VERSION ""
//Author: Matthew Nice

NS_ :

BS_:

BU_: XXX

BO_ 116 PEDAL_CMD: 12 XXX
 SG_ TORQUE_CMD_CCM : 86|12@0+ (1,0) [0|4000] "" XXX
 SG_ ACCEL_THROTTLE : 43|10@0+ (1,0) [0|4000] "" XXX
 SG_ ACCEL_PEDAL_DRIVER : 49|10@0+ (1,0) [0|4000] "" XXX

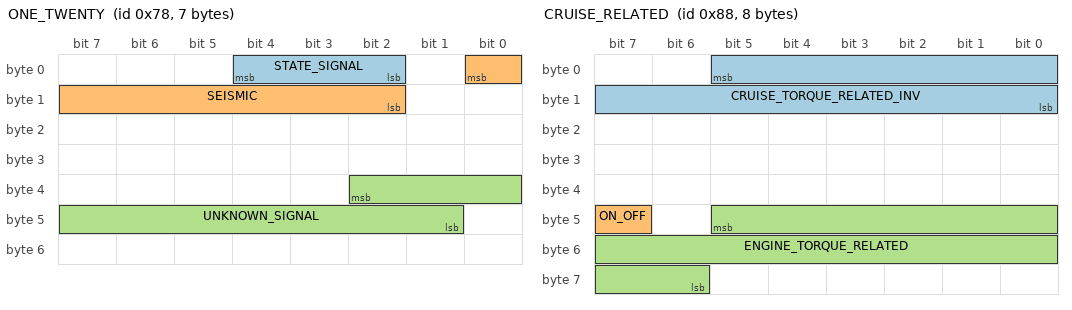
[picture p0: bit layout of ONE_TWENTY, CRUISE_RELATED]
BO_ 120 ONE_TWENTY: 7 XXX
 SG_ STATE_SIGNAL : 4|3@0+ (1,0) [0|4000] "" XXX
 SG_ SEISMIC : 0|7@0+ (1,0) [0|4000] "" XXX
 SG_ UNKNOWN_SIGNAL : 34|10@0+ (1,0) [0|4000] "" XXX

BO_ 136 CRUISE_RELATED: 8 XXX
 SG_ CRUISE_TORQUE_RELATED_INV : 5|14@0+ (1,0) [0|4000] "" XXX
 SG_ ON_OFF : 47|1@0+ (1,0) [0|1] "" XXX
 SG_ ENGINE_TORQUE_RELATED : 45|16@0+ (1,0) [0|50000] "" XXX

BO_ 139 STEER_ANGLE: 48 XXX
 SG_ STEER_ANGLE : 55|16@0+ (0.05,0) [0|500] "" XXX
 SG_ STEER_ANGLE_REPEAT : 208|16@0+ (0.05,0) [0|500] "" XXX

BO_ 140 PEDAL_THROTTLE: 48 XXX
 SG_ ACCEL_PEDAL_POSITION: 43|10@0+ (1,0) [0|1000] "" XXX
 SG_ ACCEL_PEDAL_POSITION_REPEAT: 49|10@0+ (1,0) [0|200] "" XXX
 SG_ RPM_RELATED: 86|12@0+ (0.05,0) [0|4000] "" XXX
 SG_ WHEEL_TORQUE_CMD_RELATED: 139|16@0+ (0.05,0) [0|100000] "" XXX
 SG_ RPM: 167|16@0+ (0.14285,0) [0|100000] "" XXX
 SG_ WHEEL_TORQUE_CMD_RELATED_2: 183|10@0+ (0.05,0) [0|100000] "" XXX

BO_ 141 STEERING_WHEEL: 24 XXX
 SG_ STEER_ANGLE: 55|18@0+ (1,0) [0|140000] "" XXX
 SG_ STEER_RATE: 66|12@0+ (1,0) [0|4000] "" XXX
 SG_ STEER_RELATED_YAW: 86|11@0+ (1,0) [0|1000] "" XXX

BO_ 168 STEERING_2: 24 XXX
 SG_ STEER_ANGLE: 55|12@0+ (1,0) [0|140000] "" XXX
 SG_ STEER_RATE: 79|16@0+ (1,0) [0|4000] "" XXX

BO_ 286 TWO_EIGHTY_SIX: 3 XXX
 SG_ WHEEL_TORQUE_CMD: 5|15@0+ (1,0) [0|100] "" XXX

BO_ 303 SPEED: 12 XXX
 SG_ GEAR: 55|6@0+ (1,0) [0|64] "" XXX
 SG_ WHEEL_TORQUE: 60|12@0+ (1,0) [0|4000] "" XXX
 SG_ SPEED : 77|12@0+ (0.048,0) [0|65535] "kph" XXX

BO_ 308 CRUISE: 64 XXX
 SG_ CRUISE_TORQUE_STATE : 57|4@0+ (1,0) [0|16] "" XXX
 SG_ WHEEL_TORQUE_CMD : 68|12@0+ (1,0) [0|4000] "" XXX
 SG_ STEER_ANGLE_BUT_NOT : 151|16@0+ (1,0) [0|40000] "" XXX
 SG_ BRAKE_TORQUE_ACTIVE : 160|1@0+ (1,0) [0|1] "" XXX
 SG_ BRAKE_TORQUE_CMD : 170|10@0+ (1,0) [0|1000] "" XXX
 SG_ CRUISE_STATE : 306|4@0+ (1,0) [0|32] "" XXX
 SG_ CRUISE_ENGAGED : 321|1@0+ (1,0) [0|1] "" XXX

BO_ 381 LEFT_RADAR_1: 64 Vector__XXX
	SG_ NEARBY_WARNING_FLAG_6 : 484|1@0+ (1,0) [0|0] "unit" Vector__XXX
	SG_ INVALID_6 : 473|1@0+ (1,0) [0|0] "unit" Vector__XXX
	SG_ VALID_B_6 : 475|1@0+ (1,0) [0|0] "unit" Vector__XXX
	SG_ VALID_A_6 : 478|1@0+ (1,0) [0|0] "unit" Vector__XXX
	SG_ MYSTERY_RELATIVE_VELOCITY_6 : 460|13@0- (1,0) [0|0] "unit" Vector__XXX
	SG_ ABSOLUTE_DISTANCE_6 : 442|13@0+ (0.0176,0.1163) [0|0] "m" Vector__XXX
	SG_ ANGLE_6 : 431|9@0+ (0.0033,0.4509) [0|0] "radians" Vector__XXX
	SG_ BEHIND_FLAG_6 : 416|1@0+ (1,0) [0|0] "unit" Vector_XXX
	SG_ SIGNAL_QUESTION_A_6 : 422|6@0- (1,0) [0|0] "unit" Vector__XXX

	SG_ NEARBY_WARNING_FLAG_5 : 412|1@0+ (1,0) [0|0] "unit" Vector__XXX
	SG_ INVALID_5 : 401|1@0+ (1,0) [0|0] "unit" Vector__XXX
	SG_ VALID_B_5 : 403|1@0+ (1,0) [0|0] "unit" Vector__XXX
	SG_ VALID_A_5 : 406|1@0+ (1,0) [0|0] "unit" Vector__XXX
	SG_ MYSTERY_RELATIVE_VELOCITY_5 : 388|13@0- (1,0) [0|0] "unit" Vector__XXX
	SG_ ABSOLUTE_DISTANCE_5 : 370|13@0+ (0.0176,0.1163) [0|0] "m" Vector__XXX
	SG_ ANGLE_5 : 359|9@0+ (0.0033,0.4509) [0|0] "radians" Vector__XXX
	SG_ BEHIND_FLAG_5 : 344|1@0+ (1,0) [0|0] "unit" Vector_XXX
	SG_ SIGNAL_QUESTION_A_5 : 350|6@0- (1,0) [0|0] "unit" Vector__XXX

	SG_ NEARBY_WARNING_FLAG_4 : 340|1@0+ (1,0) [0|0] "unit" Vector__XXX
	SG_ INVALID_4 : 329|1@0+ (1,0) [0|0] "unit" Vector__XXX
	SG_ VALID_B_4 : 331|1@0+ (1,0) [0|0] "unit" Vector__XXX
	SG_ VALID_A_4 : 334|1@0+ (1,0) [0|0] "unit" Vector__XXX
	SG_ MYSTERY_RELATIVE_VELOCITY_4 : 316|13@0- (1,0) [0|0] "unit" Vector__XXX
	SG_ ABSOLUTE_DISTANCE_4 : 298|13@0+ (0.0176,0.1163) [0|0] "m" Vector__XXX
	SG_ ANGLE_4 : 287|9@0+ (0.0033,0.4509) [0|0] "radians" Vector__XXX
	SG_ BEHIND_FLAG_4 : 272|1@0+ (1,0) [0|0] "unit" Vector_XXX
	SG_ SIGNAL_QUESTION_A_4 : 278|6@0- (1,0) [0|0] "unit" Vector__XXX

	SG_ NEARBY_WARNING_FLAG_3 : 268|1@0+ (1,0) [0|0] "unit" Vector__XXX
	SG_ INVALID_3 : 257|1@0+ (1,0) [0|0] "unit" Vector__XXX
	SG_ VALID_B_3 : 259|1@0+ (1,0) [0|0] "unit" Vector__XXX
	SG_ VALID_A_3 : 262|1@0+ (1,0) [0|0] "unit" Vector__XXX
	SG_ MYSTERY_RELATIVE_VELOCITY_3 : 244|13@0- (1,0) [0|0] "unit" Vector__XXX
	SG_ ABSOLUTE_DISTANCE_3 : 226|13@0+ (0.0176,0.1163) [0|0] "m" Vector__XXX
	SG_ ANGLE_3 : 215|9@0+ (0.0033,0.4509) [0|0] "radians" Vector__XXX
	SG_ BEHIND_FLAG_3 : 200|1@0+ (1,0) [0|0] "unit" Vector_XXX
	SG_ SIGNAL_QUESTION_A_3 : 206|6@0- (1,0) [0|0] "unit" Vector__XXX

	SG_ NEARBY_WARNING_FLAG_2 : 196|1@0+ (1,0) [0|0] "unit" Vector__XXX
	SG_ INVALID_2 : 185|1@0+ (1,0) [0|0] "unit" Vector__XXX
	SG_ VALID_B_2 : 187|1@0+ (1,0) [0|0] "unit" Vector__XXX
	SG_ VALID_A_2 : 190|1@0+ (1,0) [0|0] "unit" Vector__XXX
	SG_ MYSTERY_RELATIVE_VELOCITY_2 : 172|13@0- (1,0) [0|0] "unit" Vector__XXX
	SG_ ABSOLUTE_DISTANCE_2 : 154|13@0+ (0.0176,0.1163) [0|0] "m" Vector__XXX
	SG_ ANGLE_2 : 143|9@0+ (0.0033,0.4509) [0|0] "radians" Vector__XXX
	SG_ BEHIND_FLAG_2 : 128|1@0+ (1,0) [0|0] "unit" Vector_XXX
	SG_ SIGNAL_QUESTION_A_2 : 134|6@0- (1,0) [0|0] "unit" Vector__XXX

	SG_ NEARBY_WARNING_FLAG_1 : 124|1@0+ (1,0) [0|0] "unit" Vector__XXX
	SG_ INVALID_1 : 113|1@0+ (1,0) [0|0] "unit" Vector__XXX
	SG_ VALID_B_1 : 115|1@0+ (1,0) [0|0] "unit" Vector__XXX
	SG_ VALID_A_1 : 118|1@0+ (1,0) [0|0] "unit" Vector__XXX
	SG_ MYSTERY_RELATIVE_VELOCITY_1 : 100|13@0- (1,0) [0|0] "unit" Vector__XXX
	SG_ ABSOLUTE_DISTANCE_1 : 82|13@0+ (0.0176,0.1163) [0|0] "m" Vector__XXX
	SG_ ANGLE_1 : 71|9@0+ (0.0033,0.4509) [0|0] "radians" Vector__XXX
	SG_ BEHIND_FLAG_1 : 56|1@0+ (1,0) [0|0] "unit" Vector_XXX
	SG_ SIGNAL_QUESTION_A_1 : 62|6@0- (1,0) [0|0] "unit" Vector__XXX

	SG_ COUNTER : 23|8@0+ (1,0) [0|0] "unit" Vector__XXX
	SG_ CHECKSUM : 7|16@0+ (1,0) [0|0] "unit" Vector__XXX

BO_ 382 RIGHT_RADAR_1: 64 Vector__XXX
	SG_ NEARBY_WARNING_FLAG_6 : 484|1@0+ (1,0) [0|0] "unit" Vector__XXX
	SG_ INVALID_6 : 473|1@0+ (1,0) [0|0] "unit" Vector__XXX
	SG_ VALID_B_6 : 475|1@0+ (1,0) [0|0] "unit" Vector__XXX
	SG_ VALID_A_6 : 478|1@0+ (1,0) [0|0] "unit" Vector__XXX
	SG_ MYSTERY_RELATIVE_VELOCITY_6 : 460|13@0- (1,0) [0|0] "unit" Vector__XXX
	SG_ ABSOLUTE_DISTANCE_6 : 442|13@0+ (0.0176,0.1163) [0|0] "m" Vector__XXX
	SG_ ANGLE_6 : 431|9@0+ (0.0033,0.4509) [0|0] "radians" Vector__XXX
	SG_ BEHIND_FLAG_6 : 416|1@0+ (1,0) [0|0] "unit" Vector_XXX
	SG_ SIGNAL_QUESTION_A_6 : 422|6@0- (1,0) [0|0] "unit" Vector__XXX

	SG_ NEARBY_WARNING_FLAG_5 : 412|1@0+ (1,0) [0|0] "unit" Vector__XXX
	SG_ INVALID_5 : 401|1@0+ (1,0) [0|0] "unit" Vector__XXX
	SG_ VALID_B_5 : 403|1@0+ (1,0) [0|0] "unit" Vector__XXX
	SG_ VALID_A_5 : 406|1@0+ (1,0) [0|0] "unit" Vector__XXX
	SG_ MYSTERY_RELATIVE_VELOCITY_5 : 388|13@0- (1,0) [0|0] "unit" Vector__XXX
	SG_ ABSOLUTE_DISTANCE_5 : 370|13@0+ (0.0176,0.1163) [0|0] "m" Vector__XXX
	SG_ ANGLE_5 : 359|9@0+ (0.0033,0.4509) [0|0] "radians" Vector__XXX
	SG_ BEHIND_FLAG_5 : 344|1@0+ (1,0) [0|0] "unit" Vector_XXX
	SG_ SIGNAL_QUESTION_A_5 : 350|6@0- (1,0) [0|0] "unit" Vector__XXX

	SG_ NEARBY_WARNING_FLAG_4 : 340|1@0+ (1,0) [0|0] "unit" Vector__XXX
	SG_ INVALID_4 : 329|1@0+ (1,0) [0|0] "unit" Vector__XXX
	SG_ VALID_B_4 : 331|1@0+ (1,0) [0|0] "unit" Vector__XXX
	SG_ VALID_A_4 : 334|1@0+ (1,0) [0|0] "unit" Vector__XXX
	SG_ MYSTERY_RELATIVE_VELOCITY_4 : 316|13@0- (1,0) [0|0] "unit" Vector__XXX
	SG_ ABSOLUTE_DISTANCE_4 : 298|13@0+ (0.0176,0.1163) [0|0] "m" Vector__XXX
	SG_ ANGLE_4 : 287|9@0+ (0.0033,0.4509) [0|0] "radians" Vector__XXX
	SG_ BEHIND_FLAG_4 : 272|1@0+ (1,0) [0|0] "unit" Vector_XXX
	SG_ SIGNAL_QUESTION_A_4 : 278|6@0- (1,0) [0|0] "unit" Vector__XXX

	SG_ NEARBY_WARNING_FLAG_3 : 268|1@0+ (1,0) [0|0] "unit" Vector__XXX
	SG_ INVALID_3 : 257|1@0+ (1,0) [0|0] "unit" Vector__XXX
	SG_ VALID_B_3 : 259|1@0+ (1,0) [0|0] "unit" Vector__XXX
	SG_ VALID_A_3 : 262|1@0+ (1,0) [0|0] "unit" Vector__XXX
	SG_ MYSTERY_RELATIVE_VELOCITY_3 : 244|13@0- (1,0) [0|0] "unit" Vector__XXX
	SG_ ABSOLUTE_DISTANCE_3 : 226|13@0+ (0.0176,0.1163) [0|0] "m" Vector__XXX
	SG_ ANGLE_3 : 215|9@0+ (0.0033,0.4509) [0|0] "radians" Vector__XXX
	SG_ BEHIND_FLAG_3 : 200|1@0+ (1,0) [0|0] "unit" Vector_XXX
	SG_ SIGNAL_QUESTION_A_3 : 206|6@0- (1,0) [0|0] "unit" Vector__XXX

	SG_ NEARBY_WARNING_FLAG_2 : 196|1@0+ (1,0) [0|0] "unit" Vector__XXX
	SG_ INVALID_2 : 185|1@0+ (1,0) [0|0] "unit" Vector__XXX
	SG_ VALID_B_2 : 187|1@0+ (1,0) [0|0] "unit" Vector__XXX
	SG_ VALID_A_2 : 190|1@0+ (1,0) [0|0] "unit" Vector__XXX
	SG_ MYSTERY_RELATIVE_VELOCITY_2 : 172|13@0- (1,0) [0|0] "unit" Vector__XXX
	SG_ ABSOLUTE_DISTANCE_2 : 154|13@0+ (0.0176,0.1163) [0|0] "m" Vector__XXX
	SG_ ANGLE_2 : 143|9@0+ (0.0033,0.4509) [0|0] "radians" Vector__XXX
	SG_ BEHIND_FLAG_2 : 128|1@0+ (1,0) [0|0] "unit" Vector_XXX
	SG_ SIGNAL_QUESTION_A_2 : 134|6@0- (1,0) [0|0] "unit" Vector__XXX

	SG_ NEARBY_WARNING_FLAG_1 : 124|1@0+ (1,0) [0|0] "unit" Vector__XXX
	SG_ INVALID_1 : 113|1@0+ (1,0) [0|0] "unit" Vector__XXX
	SG_ VALID_B_1 : 115|1@0+ (1,0) [0|0] "unit" Vector__XXX
	SG_ VALID_A_1 : 118|1@0+ (1,0) [0|0] "unit" Vector__XXX
	SG_ MYSTERY_RELATIVE_VELOCITY_1 : 100|13@0- (1,0) [0|0] "unit" Vector__XXX
	SG_ ABSOLUTE_DISTANCE_1 : 82|13@0+ (0.0176,0.1163) [0|0] "m" Vector__XXX
	SG_ ANGLE_1 : 71|9@0+ (0.0033,0.4509) [0|0] "radians" Vector__XXX
	SG_ BEHIND_FLAG_1 : 56|1@0+ (1,0) [0|0] "unit" Vector_XXX
	SG_ SIGNAL_QUESTION_A_1 : 62|6@0- (1,0) [0|0] "unit" Vector__XXX

	SG_ COUNTER : 23|8@0+ (1,0) [0|0] "unit" Vector__XXX
	SG_ CHECKSUM : 7|16@0+ (1,0) [0|0] "unit" Vector__XXX

BO_ 385 LEFT_RADAR_2: 64 Vector__XXX
	SG_ NEARBY_WARNING_FLAG_6 : 484|1@0+ (1,0) [0|0] "unit" Vector__XXX
	SG_ INVALID_6 : 473|1@0+ (1,0) [0|0] "unit" Vector__XXX
	SG_ VALID_B_6 : 475|1@0+ (1,0) [0|0] "unit" Vector__XXX
	SG_ VALID_A_6 : 478|1@0+ (1,0) [0|0] "unit" Vector__XXX
	SG_ MYSTERY_RELATIVE_VELOCITY_6 : 460|13@0- (1,0) [0|0] "unit" Vector__XXX
	SG_ ABSOLUTE_DISTANCE_6 : 442|13@0+ (0.0176,0.1163) [0|0] "m" Vector__XXX
	SG_ ANGLE_6 : 431|9@0+ (0.0033,0.4509) [0|0] "radians" Vector__XXX
	SG_ BEHIND_FLAG_6 : 416|1@0+ (1,0) [0|0] "unit" Vector_XXX
	SG_ SIGNAL_QUESTION_A_6 : 422|6@0- (1,0) [0|0] "unit" Vector__XXX

	SG_ NEARBY_WARNING_FLAG_5 : 412|1@0+ (1,0) [0|0] "unit" Vector__XXX
	SG_ INVALID_5 : 401|1@0+ (1,0) [0|0] "unit" Vector__XXX
	SG_ VALID_B_5 : 403|1@0+ (1,0) [0|0] "unit" Vector__XXX
	SG_ VALID_A_5 : 406|1@0+ (1,0) [0|0] "unit" Vector__XXX
	SG_ MYSTERY_RELATIVE_VELOCITY_5 : 388|13@0- (1,0) [0|0] "unit" Vector__XXX
	SG_ ABSOLUTE_DISTANCE_5 : 370|13@0+ (0.0176,0.1163) [0|0] "m" Vector__XXX
	SG_ ANGLE_5 : 359|9@0+ (0.0033,0.4509) [0|0] "radians" Vector__XXX
	SG_ BEHIND_FLAG_5 : 344|1@0+ (1,0) [0|0] "unit" Vector_XXX
	SG_ SIGNAL_QUESTION_A_5 : 350|6@0- (1,0) [0|0] "unit" Vector__XXX

	SG_ NEARBY_WARNING_FLAG_4 : 340|1@0+ (1,0) [0|0] "unit" Vector__XXX
	SG_ INVALID_4 : 329|1@0+ (1,0) [0|0] "unit" Vector__XXX
	SG_ VALID_B_4 : 331|1@0+ (1,0) [0|0] "unit" Vector__XXX
	SG_ VALID_A_4 : 334|1@0+ (1,0) [0|0] "unit" Vector__XXX
	SG_ MYSTERY_RELATIVE_VELOCITY_4 : 316|13@0- (1,0) [0|0] "unit" Vector__XXX
	SG_ ABSOLUTE_DISTANCE_4 : 298|13@0+ (0.0176,0.1163) [0|0] "m" Vector__XXX
	SG_ ANGLE_4 : 287|9@0+ (0.0033,0.4509) [0|0] "radians" Vector__XXX
	SG_ BEHIND_FLAG_4 : 272|1@0+ (1,0) [0|0] "unit" Vector_XXX
	SG_ SIGNAL_QUESTION_A_4 : 278|6@0- (1,0) [0|0] "unit" Vector__XXX

	SG_ NEARBY_WARNING_FLAG_3 : 268|1@0+ (1,0) [0|0] "unit" Vector__XXX
	SG_ INVALID_3 : 257|1@0+ (1,0) [0|0] "unit" Vector__XXX
	SG_ VALID_B_3 : 259|1@0+ (1,0) [0|0] "unit" Vector__XXX
	SG_ VALID_A_3 : 262|1@0+ (1,0) [0|0] "unit" Vector__XXX
	SG_ MYSTERY_RELATIVE_VELOCITY_3 : 244|13@0- (1,0) [0|0] "unit" Vector__XXX
	SG_ ABSOLUTE_DISTANCE_3 : 226|13@0+ (0.0176,0.1163) [0|0] "m" Vector__XXX
	SG_ ANGLE_3 : 215|9@0+ (0.0033,0.4509) [0|0] "radians" Vector__XXX
	SG_ BEHIND_FLAG_3 : 200|1@0+ (1,0) [0|0] "unit" Vector_XXX
	SG_ SIGNAL_QUESTION_A_3 : 206|6@0- (1,0) [0|0] "unit" Vector__XXX

	SG_ NEARBY_WARNING_FLAG_2 : 196|1@0+ (1,0) [0|0] "unit" Vector__XXX
	SG_ INVALID_2 : 185|1@0+ (1,0) [0|0] "unit" Vector__XXX
	SG_ VALID_B_2 : 187|1@0+ (1,0) [0|0] "unit" Vector__XXX
	SG_ VALID_A_2 : 190|1@0+ (1,0) [0|0] "unit" Vector__XXX
	SG_ MYSTERY_RELATIVE_VELOCITY_2 : 172|13@0- (1,0) [0|0] "unit" Vector__XXX
	SG_ ABSOLUTE_DISTANCE_2 : 154|13@0+ (0.0176,0.1163) [0|0] "m" Vector__XXX
	SG_ ANGLE_2 : 143|9@0+ (0.0033,0.4509) [0|0] "radians" Vector__XXX
	SG_ BEHIND_FLAG_2 : 128|1@0+ (1,0) [0|0] "unit" Vector_XXX
	SG_ SIGNAL_QUESTION_A_2 : 134|6@0- (1,0) [0|0] "unit" Vector__XXX

	SG_ NEARBY_WARNING_FLAG_1 : 124|1@0+ (1,0) [0|0] "unit" Vector__XXX
	SG_ INVALID_1 : 113|1@0+ (1,0) [0|0] "unit" Vector__XXX
	SG_ VALID_B_1 : 115|1@0+ (1,0) [0|0] "unit" Vector__XXX
	SG_ VALID_A_1 : 118|1@0+ (1,0) [0|0] "unit" Vector__XXX
	SG_ MYSTERY_RELATIVE_VELOCITY_1 : 100|13@0- (1,0) [0|0] "unit" Vector__XXX
	SG_ ABSOLUTE_DISTANCE_1 : 82|13@0+ (0.0176,0.1163) [0|0] "m" Vector__XXX
	SG_ ANGLE_1 : 71|9@0+ (0.0033,0.4509) [0|0] "radians" Vector__XXX
	SG_ BEHIND_FLAG_1 : 56|1@0+ (1,0) [0|0] "unit" Vector_XXX
	SG_ SIGNAL_QUESTION_A_1 : 62|6@0- (1,0) [0|0] "unit" Vector__XXX

	SG_ COUNTER : 23|8@0+ (1,0) [0|0] "unit" Vector__XXX
	SG_ CHECKSUM : 7|16@0+ (1,0) [0|0] "unit" Vector__XXX

BO_ 386 RIGHT_RADAR_2: 64 Vector__XXX
	SG_ NEARBY_WARNING_FLAG_6 : 484|1@0+ (1,0) [0|0] "unit" Vector__XXX
	SG_ INVALID_6 : 473|1@0+ (1,0) [0|0] "unit" Vector__XXX
	SG_ VALID_B_6 : 475|1@0+ (1,0) [0|0] "unit" Vector__XXX
	SG_ VALID_A_6 : 478|1@0+ (1,0) [0|0] "unit" Vector__XXX
	SG_ MYSTERY_RELATIVE_VELOCITY_6 : 460|13@0- (1,0) [0|0] "unit" Vector__XXX
	SG_ ABSOLUTE_DISTANCE_6 : 442|13@0+ (0.0176,0.1163) [0|0] "m" Vector__XXX
	SG_ ANGLE_6 : 431|9@0+ (0.0033,0.4509) [0|0] "radians" Vector__XXX
	SG_ BEHIND_FLAG_6 : 416|1@0+ (1,0) [0|0] "unit" Vector_XXX
	SG_ SIGNAL_QUESTION_A_6 : 422|6@0- (1,0) [0|0] "unit" Vector__XXX

	SG_ NEARBY_WARNING_FLAG_5 : 412|1@0+ (1,0) [0|0] "unit" Vector__XXX
	SG_ INVALID_5 : 401|1@0+ (1,0) [0|0] "unit" Vector__XXX
	SG_ VALID_B_5 : 403|1@0+ (1,0) [0|0] "unit" Vector__XXX
	SG_ VALID_A_5 : 406|1@0+ (1,0) [0|0] "unit" Vector__XXX
	SG_ MYSTERY_RELATIVE_VELOCITY_5 : 388|13@0- (1,0) [0|0] "unit" Vector__XXX
	SG_ ABSOLUTE_DISTANCE_5 : 370|13@0+ (0.0176,0.1163) [0|0] "m" Vector__XXX
	SG_ ANGLE_5 : 359|9@0+ (0.0033,0.4509) [0|0] "radians" Vector__XXX
	SG_ BEHIND_FLAG_5 : 344|1@0+ (1,0) [0|0] "unit" Vector_XXX
	SG_ SIGNAL_QUESTION_A_5 : 350|6@0- (1,0) [0|0] "unit" Vector__XXX

	SG_ NEARBY_WARNING_FLAG_4 : 340|1@0+ (1,0) [0|0] "unit" Vector__XXX
	SG_ INVALID_4 : 329|1@0+ (1,0) [0|0] "unit" Vector__XXX
	SG_ VALID_B_4 : 331|1@0+ (1,0) [0|0] "unit" Vector__XXX
	SG_ VALID_A_4 : 334|1@0+ (1,0) [0|0] "unit" Vector__XXX
	SG_ MYSTERY_RELATIVE_VELOCITY_4 : 316|13@0- (1,0) [0|0] "unit" Vector__XXX
	SG_ ABSOLUTE_DISTANCE_4 : 298|13@0+ (0.0176,0.1163) [0|0] "m" Vector__XXX
	SG_ ANGLE_4 : 287|9@0+ (0.0033,0.4509) [0|0] "radians" Vector__XXX
	SG_ BEHIND_FLAG_4 : 272|1@0+ (1,0) [0|0] "unit" Vector_XXX
	SG_ SIGNAL_QUESTION_A_4 : 278|6@0- (1,0) [0|0] "unit" Vector__XXX

	SG_ NEARBY_WARNING_FLAG_3 : 268|1@0+ (1,0) [0|0] "unit" Vector__XXX
	SG_ INVALID_3 : 257|1@0+ (1,0) [0|0] "unit" Vector__XXX
	SG_ VALID_B_3 : 259|1@0+ (1,0) [0|0] "unit" Vector__XXX
	SG_ VALID_A_3 : 262|1@0+ (1,0) [0|0] "unit" Vector__XXX
	SG_ MYSTERY_RELATIVE_VELOCITY_3 : 244|13@0- (1,0) [0|0] "unit" Vector__XXX
	SG_ ABSOLUTE_DISTANCE_3 : 226|13@0+ (0.0176,0.1163) [0|0] "m" Vector__XXX
	SG_ ANGLE_3 : 215|9@0+ (0.0033,0.4509) [0|0] "radians" Vector__XXX
	SG_ BEHIND_FLAG_3 : 200|1@0+ (1,0) [0|0] "unit" Vector_XXX
	SG_ SIGNAL_QUESTION_A_3 : 206|6@0- (1,0) [0|0] "unit" Vector__XXX

	SG_ NEARBY_WARNING_FLAG_2 : 196|1@0+ (1,0) [0|0] "unit" Vector__XXX
	SG_ INVALID_2 : 185|1@0+ (1,0) [0|0] "unit" Vector__XXX
	SG_ VALID_B_2 : 187|1@0+ (1,0) [0|0] "unit" Vector__XXX
	SG_ VALID_A_2 : 190|1@0+ (1,0) [0|0] "unit" Vector__XXX
	SG_ MYSTERY_RELATIVE_VELOCITY_2 : 172|13@0- (1,0) [0|0] "unit" Vector__XXX
	SG_ ABSOLUTE_DISTANCE_2 : 154|13@0+ (0.0176,0.1163) [0|0] "m" Vector__XXX
	SG_ ANGLE_2 : 143|9@0+ (0.0033,0.4509) [0|0] "radians" Vector__XXX
	SG_ BEHIND_FLAG_2 : 128|1@0+ (1,0) [0|0] "unit" Vector_XXX
	SG_ SIGNAL_QUESTION_A_2 : 134|6@0- (1,0) [0|0] "unit" Vector__XXX

	SG_ NEARBY_WARNING_FLAG_1 : 124|1@0+ (1,0) [0|0] "unit" Vector__XXX
	SG_ INVALID_1 : 113|1@0+ (1,0) [0|0] "unit" Vector__XXX
	SG_ VALID_B_1 : 115|1@0+ (1,0) [0|0] "unit" Vector__XXX
	SG_ VALID_A_1 : 118|1@0+ (1,0) [0|0] "unit" Vector__XXX
	SG_ MYSTERY_RELATIVE_VELOCITY_1 : 100|13@0- (1,0) [0|0] "unit" Vector__XXX
	SG_ ABSOLUTE_DISTANCE_1 : 82|13@0+ (0.0176,0.1163) [0|0] "m" Vector__XXX
	SG_ ANGLE_1 : 71|9@0+ (0.0033,0.4509) [0|0] "radians" Vector__XXX
	SG_ BEHIND_FLAG_1 : 56|1@0+ (1,0) [0|0] "unit" Vector_XXX
	SG_ SIGNAL_QUESTION_A_1 : 62|6@0- (1,0) [0|0] "unit" Vector__XXX

	SG_ COUNTER : 23|8@0+ (1,0) [0|0] "unit" Vector__XXX
	SG_ CHECKSUM : 7|16@0+ (1,0) [0|0] "unit" Vector__XXX

BO_ 389 LEFT_RADAR_3: 64 Vector__XXX
	SG_ NEARBY_WARNING_FLAG_6 : 484|1@0+ (1,0) [0|0] "unit" Vector__XXX
	SG_ INVALID_6 : 473|1@0+ (1,0) [0|0] "unit" Vector__XXX
	SG_ VALID_B_6 : 475|1@0+ (1,0) [0|0] "unit" Vector__XXX
	SG_ VALID_A_6 : 478|1@0+ (1,0) [0|0] "unit" Vector__XXX
	SG_ MYSTERY_RELATIVE_VELOCITY_6 : 460|13@0- (1,0) [0|0] "unit" Vector__XXX
	SG_ ABSOLUTE_DISTANCE_6 : 442|13@0+ (0.0176,0.1163) [0|0] "m" Vector__XXX
	SG_ ANGLE_6 : 431|9@0+ (0.0033,0.4509) [0|0] "radians" Vector__XXX
	SG_ BEHIND_FLAG_6 : 416|1@0+ (1,0) [0|0] "unit" Vector_XXX
	SG_ SIGNAL_QUESTION_A_6 : 422|6@0- (1,0) [0|0] "unit" Vector__XXX

	SG_ NEARBY_WARNING_FLAG_5 : 412|1@0+ (1,0) [0|0] "unit" Vector__XXX
	SG_ INVALID_5 : 401|1@0+ (1,0) [0|0] "unit" Vector__XXX
	SG_ VALID_B_5 : 403|1@0+ (1,0) [0|0] "unit" Vector__XXX
	SG_ VALID_A_5 : 406|1@0+ (1,0) [0|0] "unit" Vector__XXX
	SG_ MYSTERY_RELATIVE_VELOCITY_5 : 388|13@0- (1,0) [0|0] "unit" Vector__XXX
	SG_ ABSOLUTE_DISTANCE_5 : 370|13@0+ (0.0176,0.1163) [0|0] "m" Vector__XXX
	SG_ ANGLE_5 : 359|9@0+ (0.0033,0.4509) [0|0] "radians" Vector__XXX
	SG_ BEHIND_FLAG_5 : 344|1@0+ (1,0) [0|0] "unit" Vector_XXX
	SG_ SIGNAL_QUESTION_A_5 : 350|6@0- (1,0) [0|0] "unit" Vector__XXX

	SG_ NEARBY_WARNING_FLAG_4 : 340|1@0+ (1,0) [0|0] "unit" Vector__XXX
	SG_ INVALID_4 : 329|1@0+ (1,0) [0|0] "unit" Vector__XXX
	SG_ VALID_B_4 : 331|1@0+ (1,0) [0|0] "unit" Vector__XXX
	SG_ VALID_A_4 : 334|1@0+ (1,0) [0|0] "unit" Vector__XXX
	SG_ MYSTERY_RELATIVE_VELOCITY_4 : 316|13@0- (1,0) [0|0] "unit" Vector__XXX
	SG_ ABSOLUTE_DISTANCE_4 : 298|13@0+ (0.0176,0.1163) [0|0] "m" Vector__XXX
	SG_ ANGLE_4 : 287|9@0+ (0.0033,0.4509) [0|0] "radians" Vector__XXX
	SG_ BEHIND_FLAG_4 : 272|1@0+ (1,0) [0|0] "unit" Vector_XXX
	SG_ SIGNAL_QUESTION_A_4 : 278|6@0- (1,0) [0|0] "unit" Vector__XXX

	SG_ NEARBY_WARNING_FLAG_3 : 268|1@0+ (1,0) [0|0] "unit" Vector__XXX
	SG_ INVALID_3 : 257|1@0+ (1,0) [0|0] "unit" Vector__XXX
	SG_ VALID_B_3 : 259|1@0+ (1,0) [0|0] "unit" Vector__XXX
	SG_ VALID_A_3 : 262|1@0+ (1,0) [0|0] "unit" Vector__XXX
	SG_ MYSTERY_RELATIVE_VELOCITY_3 : 244|13@0- (1,0) [0|0] "unit" Vector__XXX
	SG_ ABSOLUTE_DISTANCE_3 : 226|13@0+ (0.0176,0.1163) [0|0] "m" Vector__XXX
	SG_ ANGLE_3 : 215|9@0+ (0.0033,0.4509) [0|0] "radians" Vector__XXX
	SG_ BEHIND_FLAG_3 : 200|1@0+ (1,0) [0|0] "unit" Vector_XXX
	SG_ SIGNAL_QUESTION_A_3 : 206|6@0- (1,0) [0|0] "unit" Vector__XXX

	SG_ NEARBY_WARNING_FLAG_2 : 196|1@0+ (1,0) [0|0] "unit" Vector__XXX
	SG_ INVALID_2 : 185|1@0+ (1,0) [0|0] "unit" Vector__XXX
	SG_ VALID_B_2 : 187|1@0+ (1,0) [0|0] "unit" Vector__XXX
	SG_ VALID_A_2 : 190|1@0+ (1,0) [0|0] "unit" Vector__XXX
	SG_ MYSTERY_RELATIVE_VELOCITY_2 : 172|13@0- (1,0) [0|0] "unit" Vector__XXX
	SG_ ABSOLUTE_DISTANCE_2 : 154|13@0+ (0.0176,0.1163) [0|0] "m" Vector__XXX
	SG_ ANGLE_2 : 143|9@0+ (0.0033,0.4509) [0|0] "radians" Vector__XXX
	SG_ BEHIND_FLAG_2 : 128|1@0+ (1,0) [0|0] "unit" Vector_XXX
	SG_ SIGNAL_QUESTION_A_2 : 134|6@0- (1,0) [0|0] "unit" Vector__XXX

	SG_ NEARBY_WARNING_FLAG_1 : 124|1@0+ (1,0) [0|0] "unit" Vector__XXX
	SG_ INVALID_1 : 113|1@0+ (1,0) [0|0] "unit" Vector__XXX
	SG_ VALID_B_1 : 115|1@0+ (1,0) [0|0] "unit" Vector__XXX
	SG_ VALID_A_1 : 118|1@0+ (1,0) [0|0] "unit" Vector__XXX
	SG_ MYSTERY_RELATIVE_VELOCITY_1 : 100|13@0- (1,0) [0|0] "unit" Vector__XXX
	SG_ ABSOLUTE_DISTANCE_1 : 82|13@0+ (0.0176,0.1163) [0|0] "m" Vector__XXX
	SG_ ANGLE_1 : 71|9@0+ (0.0033,0.4509) [0|0] "radians" Vector__XXX
	SG_ BEHIND_FLAG_1 : 56|1@0+ (1,0) [0|0] "unit" Vector_XXX
	SG_ SIGNAL_QUESTION_A_1 : 62|6@0- (1,0) [0|0] "unit" Vector__XXX

	SG_ COUNTER : 23|8@0+ (1,0) [0|0] "unit" Vector__XXX
	SG_ CHECKSUM : 7|16@0+ (1,0) [0|0] "unit" Vector__XXX

BO_ 390 RIGHT_RADAR_3: 64 Vector__XXX
	SG_ NEARBY_WARNING_FLAG_6 : 484|1@0+ (1,0) [0|0] "unit" Vector__XXX
	SG_ INVALID_6 : 473|1@0+ (1,0) [0|0] "unit" Vector__XXX
	SG_ VALID_B_6 : 475|1@0+ (1,0) [0|0] "unit" Vector__XXX
	SG_ VALID_A_6 : 478|1@0+ (1,0) [0|0] "unit" Vector__XXX
	SG_ MYSTERY_RELATIVE_VELOCITY_6 : 460|13@0- (1,0) [0|0] "unit" Vector__XXX
	SG_ ABSOLUTE_DISTANCE_6 : 442|13@0+ (0.0176,0.1163) [0|0] "m" Vector__XXX
	SG_ ANGLE_6 : 431|9@0+ (0.0033,0.4509) [0|0] "radians" Vector__XXX
	SG_ BEHIND_FLAG_6 : 416|1@0+ (1,0) [0|0] "unit" Vector_XXX
	SG_ SIGNAL_QUESTION_A_6 : 422|6@0- (1,0) [0|0] "unit" Vector__XXX

	SG_ NEARBY_WARNING_FLAG_5 : 412|1@0+ (1,0) [0|0] "unit" Vector__XXX
	SG_ INVALID_5 : 401|1@0+ (1,0) [0|0] "unit" Vector__XXX
	SG_ VALID_B_5 : 403|1@0+ (1,0) [0|0] "unit" Vector__XXX
	SG_ VALID_A_5 : 406|1@0+ (1,0) [0|0] "unit" Vector__XXX
	SG_ MYSTERY_RELATIVE_VELOCITY_5 : 388|13@0- (1,0) [0|0] "unit" Vector__XXX
	SG_ ABSOLUTE_DISTANCE_5 : 370|13@0+ (0.0176,0.1163) [0|0] "m" Vector__XXX
	SG_ ANGLE_5 : 359|9@0+ (0.0033,0.4509) [0|0] "radians" Vector__XXX
	SG_ BEHIND_FLAG_5 : 344|1@0+ (1,0) [0|0] "unit" Vector_XXX
	SG_ SIGNAL_QUESTION_A_5 : 350|6@0- (1,0) [0|0] "unit" Vector__XXX

	SG_ NEARBY_WARNING_FLAG_4 : 340|1@0+ (1,0) [0|0] "unit" Vector__XXX
	SG_ INVALID_4 : 329|1@0+ (1,0) [0|0] "unit" Vector__XXX
	SG_ VALID_B_4 : 331|1@0+ (1,0) [0|0] "unit" Vector__XXX
	SG_ VALID_A_4 : 334|1@0+ (1,0) [0|0] "unit" Vector__XXX
	SG_ MYSTERY_RELATIVE_VELOCITY_4 : 316|13@0- (1,0) [0|0] "unit" Vector__XXX
	SG_ ABSOLUTE_DISTANCE_4 : 298|13@0+ (0.0176,0.1163) [0|0] "m" Vector__XXX
	SG_ ANGLE_4 : 287|9@0+ (0.0033,0.4509) [0|0] "radians" Vector__XXX
	SG_ BEHIND_FLAG_4 : 272|1@0+ (1,0) [0|0] "unit" Vector_XXX
	SG_ SIGNAL_QUESTION_A_4 : 278|6@0- (1,0) [0|0] "unit" Vector__XXX

	SG_ NEARBY_WARNING_FLAG_3 : 268|1@0+ (1,0) [0|0] "unit" Vector__XXX
	SG_ INVALID_3 : 257|1@0+ (1,0) [0|0] "unit" Vector__XXX
	SG_ VALID_B_3 : 259|1@0+ (1,0) [0|0] "unit" Vector__XXX
	SG_ VALID_A_3 : 262|1@0+ (1,0) [0|0] "unit" Vector__XXX
	SG_ MYSTERY_RELATIVE_VELOCITY_3 : 244|13@0- (1,0) [0|0] "unit" Vector__XXX
	SG_ ABSOLUTE_DISTANCE_3 : 226|13@0+ (0.0176,0.1163) [0|0] "m" Vector__XXX
	SG_ ANGLE_3 : 215|9@0+ (0.0033,0.4509) [0|0] "radians" Vector__XXX
	SG_ BEHIND_FLAG_3 : 200|1@0+ (1,0) [0|0] "unit" Vector_XXX
	SG_ SIGNAL_QUESTION_A_3 : 206|6@0- (1,0) [0|0] "unit" Vector__XXX

	SG_ NEARBY_WARNING_FLAG_2 : 196|1@0+ (1,0) [0|0] "unit" Vector__XXX
	SG_ INVALID_2 : 185|1@0+ (1,0) [0|0] "unit" Vector__XXX
	SG_ VALID_B_2 : 187|1@0+ (1,0) [0|0] "unit" Vector__XXX
	SG_ VALID_A_2 : 190|1@0+ (1,0) [0|0] "unit" Vector__XXX
	SG_ MYSTERY_RELATIVE_VELOCITY_2 : 172|13@0- (1,0) [0|0] "unit" Vector__XXX
	SG_ ABSOLUTE_DISTANCE_2 : 154|13@0+ (0.0176,0.1163) [0|0] "m" Vector__XXX
	SG_ ANGLE_2 : 143|9@0+ (0.0033,0.4509) [0|0] "radians" Vector__XXX
	SG_ BEHIND_FLAG_2 : 128|1@0+ (1,0) [0|0] "unit" Vector_XXX
	SG_ SIGNAL_QUESTION_A_2 : 134|6@0- (1,0) [0|0] "unit" Vector__XXX

	SG_ NEARBY_WARNING_FLAG_1 : 124|1@0+ (1,0) [0|0] "unit" Vector__XXX
	SG_ INVALID_1 : 113|1@0+ (1,0) [0|0] "unit" Vector__XXX
	SG_ VALID_B_1 : 115|1@0+ (1,0) [0|0] "unit" Vector__XXX
	SG_ VALID_A_1 : 118|1@0+ (1,0) [0|0] "unit" Vector__XXX
	SG_ MYSTERY_RELATIVE_VELOCITY_1 : 100|13@0- (1,0) [0|0] "unit" Vector__XXX
	SG_ ABSOLUTE_DISTANCE_1 : 82|13@0+ (0.0176,0.1163) [0|0] "m" Vector__XXX
	SG_ ANGLE_1 : 71|9@0+ (0.0033,0.4509) [0|0] "radians" Vector__XXX
	SG_ BEHIND_FLAG_1 : 56|1@0+ (1,0) [0|0] "unit" Vector_XXX
	SG_ SIGNAL_QUESTION_A_1 : 62|6@0- (1,0) [0|0] "unit" Vector__XXX

	SG_ COUNTER : 23|8@0+ (1,0) [0|0] "unit" Vector__XXX
	SG_ CHECKSUM : 7|16@0+ (1,0) [0|0] "unit" Vector__XXX

BO_ 393 LEFT_RADAR_4: 64 Vector__XXX
	SG_ NEARBY_WARNING_FLAG_6 : 484|1@0+ (1,0) [0|0] "unit" Vector__XXX
	SG_ INVALID_6 : 473|1@0+ (1,0) [0|0] "unit" Vector__XXX
	SG_ VALID_B_6 : 475|1@0+ (1,0) [0|0] "unit" Vector__XXX
	SG_ VALID_A_6 : 478|1@0+ (1,0) [0|0] "unit" Vector__XXX
	SG_ MYSTERY_RELATIVE_VELOCITY_6 : 460|13@0- (1,0) [0|0] "unit" Vector__XXX
	SG_ ABSOLUTE_DISTANCE_6 : 442|13@0+ (0.0176,0.1163) [0|0] "m" Vector__XXX
	SG_ ANGLE_6 : 431|9@0+ (0.0033,0.4509) [0|0] "radians" Vector__XXX
	SG_ BEHIND_FLAG_6 : 416|1@0+ (1,0) [0|0] "unit" Vector_XXX
	SG_ SIGNAL_QUESTION_A_6 : 422|6@0- (1,0) [0|0] "unit" Vector__XXX

	SG_ NEARBY_WARNING_FLAG_5 : 412|1@0+ (1,0) [0|0] "unit" Vector__XXX
	SG_ INVALID_5 : 401|1@0+ (1,0) [0|0] "unit" Vector__XXX
	SG_ VALID_B_5 : 403|1@0+ (1,0) [0|0] "unit" Vector__XXX
	SG_ VALID_A_5 : 406|1@0+ (1,0) [0|0] "unit" Vector__XXX
	SG_ MYSTERY_RELATIVE_VELOCITY_5 : 388|13@0- (1,0) [0|0] "unit" Vector__XXX
	SG_ ABSOLUTE_DISTANCE_5 : 370|13@0+ (0.0176,0.1163) [0|0] "m" Vector__XXX
	SG_ ANGLE_5 : 359|9@0+ (0.0033,0.4509) [0|0] "radians" Vector__XXX
	SG_ BEHIND_FLAG_5 : 344|1@0+ (1,0) [0|0] "unit" Vector_XXX
	SG_ SIGNAL_QUESTION_A_5 : 350|6@0- (1,0) [0|0] "unit" Vector__XXX

	SG_ NEARBY_WARNING_FLAG_4 : 340|1@0+ (1,0) [0|0] "unit" Vector__XXX
	SG_ INVALID_4 : 329|1@0+ (1,0) [0|0] "unit" Vector__XXX
	SG_ VALID_B_4 : 331|1@0+ (1,0) [0|0] "unit" Vector__XXX
	SG_ VALID_A_4 : 334|1@0+ (1,0) [0|0] "unit" Vector__XXX
	SG_ MYSTERY_RELATIVE_VELOCITY_4 : 316|13@0- (1,0) [0|0] "unit" Vector__XXX
	SG_ ABSOLUTE_DISTANCE_4 : 298|13@0+ (0.0176,0.1163) [0|0] "m" Vector__XXX
	SG_ ANGLE_4 : 287|9@0+ (0.0033,0.4509) [0|0] "radians" Vector__XXX
	SG_ BEHIND_FLAG_4 : 272|1@0+ (1,0) [0|0] "unit" Vector_XXX
	SG_ SIGNAL_QUESTION_A_4 : 278|6@0- (1,0) [0|0] "unit" Vector__XXX

	SG_ NEARBY_WARNING_FLAG_3 : 268|1@0+ (1,0) [0|0] "unit" Vector__XXX
	SG_ INVALID_3 : 257|1@0+ (1,0) [0|0] "unit" Vector__XXX
	SG_ VALID_B_3 : 259|1@0+ (1,0) [0|0] "unit" Vector__XXX
	SG_ VALID_A_3 : 262|1@0+ (1,0) [0|0] "unit" Vector__XXX
	SG_ MYSTERY_RELATIVE_VELOCITY_3 : 244|13@0- (1,0) [0|0] "unit" Vector__XXX
	SG_ ABSOLUTE_DISTANCE_3 : 226|13@0+ (0.0176,0.1163) [0|0] "m" Vector__XXX
	SG_ ANGLE_3 : 215|9@0+ (0.0033,0.4509) [0|0] "radians" Vector__XXX
	SG_ BEHIND_FLAG_3 : 200|1@0+ (1,0) [0|0] "unit" Vector_XXX
	SG_ SIGNAL_QUESTION_A_3 : 206|6@0- (1,0) [0|0] "unit" Vector__XXX

	SG_ NEARBY_WARNING_FLAG_2 : 196|1@0+ (1,0) [0|0] "unit" Vector__XXX
	SG_ INVALID_2 : 185|1@0+ (1,0) [0|0] "unit" Vector__XXX
	SG_ VALID_B_2 : 187|1@0+ (1,0) [0|0] "unit" Vector__XXX
	SG_ VALID_A_2 : 190|1@0+ (1,0) [0|0] "unit" Vector__XXX
	SG_ MYSTERY_RELATIVE_VELOCITY_2 : 172|13@0- (1,0) [0|0] "unit" Vector__XXX
	SG_ ABSOLUTE_DISTANCE_2 : 154|13@0+ (0.0176,0.1163) [0|0] "m" Vector__XXX
	SG_ ANGLE_2 : 143|9@0+ (0.0033,0.4509) [0|0] "radians" Vector__XXX
	SG_ BEHIND_FLAG_2 : 128|1@0+ (1,0) [0|0] "unit" Vector_XXX
	SG_ SIGNAL_QUESTION_A_2 : 134|6@0- (1,0) [0|0] "unit" Vector__XXX

	SG_ NEARBY_WARNING_FLAG_1 : 124|1@0+ (1,0) [0|0] "unit" Vector__XXX
	SG_ INVALID_1 : 113|1@0+ (1,0) [0|0] "unit" Vector__XXX
	SG_ VALID_B_1 : 115|1@0+ (1,0) [0|0] "unit" Vector__XXX
	SG_ VALID_A_1 : 118|1@0+ (1,0) [0|0] "unit" Vector__XXX
	SG_ MYSTERY_RELATIVE_VELOCITY_1 : 100|13@0- (1,0) [0|0] "unit" Vector__XXX
	SG_ ABSOLUTE_DISTANCE_1 : 82|13@0+ (0.0176,0.1163) [0|0] "m" Vector__XXX
	SG_ ANGLE_1 : 71|9@0+ (0.0033,0.4509) [0|0] "radians" Vector__XXX
	SG_ BEHIND_FLAG_1 : 56|1@0+ (1,0) [0|0] "unit" Vector_XXX
	SG_ SIGNAL_QUESTION_A_1 : 62|6@0- (1,0) [0|0] "unit" Vector__XXX

	SG_ COUNTER : 23|8@0+ (1,0) [0|0] "unit" Vector__XXX
	SG_ CHECKSUM : 7|16@0+ (1,0) [0|0] "unit" Vector__XXX

BO_ 394 RIGHT_RADAR_4: 64 Vector__XXX
	SG_ NEARBY_WARNING_FLAG_6 : 484|1@0+ (1,0) [0|0] "unit" Vector__XXX
	SG_ INVALID_6 : 473|1@0+ (1,0) [0|0] "unit" Vector__XXX
	SG_ VALID_B_6 : 475|1@0+ (1,0) [0|0] "unit" Vector__XXX
	SG_ VALID_A_6 : 478|1@0+ (1,0) [0|0] "unit" Vector__XXX
	SG_ MYSTERY_RELATIVE_VELOCITY_6 : 460|13@0- (1,0) [0|0] "unit" Vector__XXX
	SG_ ABSOLUTE_DISTANCE_6 : 442|13@0+ (0.0176,0.1163) [0|0] "m" Vector__XXX
	SG_ ANGLE_6 : 431|9@0+ (0.0033,0.4509) [0|0] "radians" Vector__XXX
	SG_ BEHIND_FLAG_6 : 416|1@0+ (1,0) [0|0] "unit" Vector_XXX
	SG_ SIGNAL_QUESTION_A_6 : 422|6@0- (1,0) [0|0] "unit" Vector__XXX

	SG_ NEARBY_WARNING_FLAG_5 : 412|1@0+ (1,0) [0|0] "unit" Vector__XXX
	SG_ INVALID_5 : 401|1@0+ (1,0) [0|0] "unit" Vector__XXX
	SG_ VALID_B_5 : 403|1@0+ (1,0) [0|0] "unit" Vector__XXX
	SG_ VALID_A_5 : 406|1@0+ (1,0) [0|0] "unit" Vector__XXX
	SG_ MYSTERY_RELATIVE_VELOCITY_5 : 388|13@0- (1,0) [0|0] "unit" Vector__XXX
	SG_ ABSOLUTE_DISTANCE_5 : 370|13@0+ (0.0176,0.1163) [0|0] "m" Vector__XXX
	SG_ ANGLE_5 : 359|9@0+ (0.0033,0.4509) [0|0] "radians" Vector__XXX
	SG_ BEHIND_FLAG_5 : 344|1@0+ (1,0) [0|0] "unit" Vector_XXX
	SG_ SIGNAL_QUESTION_A_5 : 350|6@0- (1,0) [0|0] "unit" Vector__XXX

	SG_ NEARBY_WARNING_FLAG_4 : 340|1@0+ (1,0) [0|0] "unit" Vector__XXX
	SG_ INVALID_4 : 329|1@0+ (1,0) [0|0] "unit" Vector__XXX
	SG_ VALID_B_4 : 331|1@0+ (1,0) [0|0] "unit" Vector__XXX
	SG_ VALID_A_4 : 334|1@0+ (1,0) [0|0] "unit" Vector__XXX
	SG_ MYSTERY_RELATIVE_VELOCITY_4 : 316|13@0- (1,0) [0|0] "unit" Vector__XXX
	SG_ ABSOLUTE_DISTANCE_4 : 298|13@0+ (0.0176,0.1163) [0|0] "m" Vector__XXX
	SG_ ANGLE_4 : 287|9@0+ (0.0033,0.4509) [0|0] "radians" Vector__XXX
	SG_ BEHIND_FLAG_4 : 272|1@0+ (1,0) [0|0] "unit" Vector_XXX
	SG_ SIGNAL_QUESTION_A_4 : 278|6@0- (1,0) [0|0] "unit" Vector__XXX

	SG_ NEARBY_WARNING_FLAG_3 : 268|1@0+ (1,0) [0|0] "unit" Vector__XXX
	SG_ INVALID_3 : 257|1@0+ (1,0) [0|0] "unit" Vector__XXX
	SG_ VALID_B_3 : 259|1@0+ (1,0) [0|0] "unit" Vector__XXX
	SG_ VALID_A_3 : 262|1@0+ (1,0) [0|0] "unit" Vector__XXX
	SG_ MYSTERY_RELATIVE_VELOCITY_3 : 244|13@0- (1,0) [0|0] "unit" Vector__XXX
	SG_ ABSOLUTE_DISTANCE_3 : 226|13@0+ (0.0176,0.1163) [0|0] "m" Vector__XXX
	SG_ ANGLE_3 : 215|9@0+ (0.0033,0.4509) [0|0] "radians" Vector__XXX
	SG_ BEHIND_FLAG_3 : 200|1@0+ (1,0) [0|0] "unit" Vector_XXX
	SG_ SIGNAL_QUESTION_A_3 : 206|6@0- (1,0) [0|0] "unit" Vector__XXX

	SG_ NEARBY_WARNING_FLAG_2 : 196|1@0+ (1,0) [0|0] "unit" Vector__XXX
	SG_ INVALID_2 : 185|1@0+ (1,0) [0|0] "unit" Vector__XXX
	SG_ VALID_B_2 : 187|1@0+ (1,0) [0|0] "unit" Vector__XXX
	SG_ VALID_A_2 : 190|1@0+ (1,0) [0|0] "unit" Vector__XXX
	SG_ MYSTERY_RELATIVE_VELOCITY_2 : 172|13@0- (1,0) [0|0] "unit" Vector__XXX
	SG_ ABSOLUTE_DISTANCE_2 : 154|13@0+ (0.0176,0.1163) [0|0] "m" Vector__XXX
	SG_ ANGLE_2 : 143|9@0+ (0.0033,0.4509) [0|0] "radians" Vector__XXX
	SG_ BEHIND_FLAG_2 : 128|1@0+ (1,0) [0|0] "unit" Vector_XXX
	SG_ SIGNAL_QUESTION_A_2 : 134|6@0- (1,0) [0|0] "unit" Vector__XXX

	SG_ NEARBY_WARNING_FLAG_1 : 124|1@0+ (1,0) [0|0] "unit" Vector__XXX
	SG_ INVALID_1 : 113|1@0+ (1,0) [0|0] "unit" Vector__XXX
	SG_ VALID_B_1 : 115|1@0+ (1,0) [0|0] "unit" Vector__XXX
	SG_ VALID_A_1 : 118|1@0+ (1,0) [0|0] "unit" Vector__XXX
	SG_ MYSTERY_RELATIVE_VELOCITY_1 : 100|13@0- (1,0) [0|0] "unit" Vector__XXX
	SG_ ABSOLUTE_DISTANCE_1 : 82|13@0+ (0.0176,0.1163) [0|0] "m" Vector__XXX
	SG_ ANGLE_1 : 71|9@0+ (0.0033,0.4509) [0|0] "radians" Vector__XXX
	SG_ BEHIND_FLAG_1 : 56|1@0+ (1,0) [0|0] "unit" Vector_XXX
	SG_ SIGNAL_QUESTION_A_1 : 62|6@0- (1,0) [0|0] "unit" Vector__XXX

	SG_ COUNTER : 23|8@0+ (1,0) [0|0] "unit" Vector__XXX
	SG_ CHECKSUM : 7|16@0+ (1,0) [0|0] "unit" Vector__XXX

BO_ 398 LEFT_RADAR_5: 64 Vector__XXX
	SG_ NEARBY_WARNING_FLAG_6 : 484|1@0+ (1,0) [0|0] "unit" Vector__XXX
	SG_ INVALID_6 : 473|1@0+ (1,0) [0|0] "unit" Vector__XXX
	SG_ VALID_B_6 : 475|1@0+ (1,0) [0|0] "unit" Vector__XXX
	SG_ VALID_A_6 : 478|1@0+ (1,0) [0|0] "unit" Vector__XXX
	SG_ MYSTERY_RELATIVE_VELOCITY_6 : 460|13@0- (1,0) [0|0] "unit" Vector__XXX
	SG_ ABSOLUTE_DISTANCE_6 : 442|13@0+ (0.0176,0.1163) [0|0] "m" Vector__XXX
	SG_ ANGLE_6 : 431|9@0+ (0.0033,0.4509) [0|0] "radians" Vector__XXX
	SG_ BEHIND_FLAG_6 : 416|1@0+ (1,0) [0|0] "unit" Vector_XXX
	SG_ SIGNAL_QUESTION_A_6 : 422|6@0- (1,0) [0|0] "unit" Vector__XXX

	SG_ NEARBY_WARNING_FLAG_5 : 412|1@0+ (1,0) [0|0] "unit" Vector__XXX
	SG_ INVALID_5 : 401|1@0+ (1,0) [0|0] "unit" Vector__XXX
	SG_ VALID_B_5 : 403|1@0+ (1,0) [0|0] "unit" Vector__XXX
	SG_ VALID_A_5 : 406|1@0+ (1,0) [0|0] "unit" Vector__XXX
	SG_ MYSTERY_RELATIVE_VELOCITY_5 : 388|13@0- (1,0) [0|0] "unit" Vector__XXX
	SG_ ABSOLUTE_DISTANCE_5 : 370|13@0+ (0.0176,0.1163) [0|0] "m" Vector__XXX
	SG_ ANGLE_5 : 359|9@0+ (0.0033,0.4509) [0|0] "radians" Vector__XXX
	SG_ BEHIND_FLAG_5 : 344|1@0+ (1,0) [0|0] "unit" Vector_XXX
	SG_ SIGNAL_QUESTION_A_5 : 350|6@0- (1,0) [0|0] "unit" Vector__XXX

	SG_ NEARBY_WARNING_FLAG_4 : 340|1@0+ (1,0) [0|0] "unit" Vector__XXX
	SG_ INVALID_4 : 329|1@0+ (1,0) [0|0] "unit" Vector__XXX
	SG_ VALID_B_4 : 331|1@0+ (1,0) [0|0] "unit" Vector__XXX
	SG_ VALID_A_4 : 334|1@0+ (1,0) [0|0] "unit" Vector__XXX
	SG_ MYSTERY_RELATIVE_VELOCITY_4 : 316|13@0- (1,0) [0|0] "unit" Vector__XXX
	SG_ ABSOLUTE_DISTANCE_4 : 298|13@0+ (0.0176,0.1163) [0|0] "m" Vector__XXX
	SG_ ANGLE_4 : 287|9@0+ (0.0033,0.4509) [0|0] "radians" Vector__XXX
	SG_ BEHIND_FLAG_4 : 272|1@0+ (1,0) [0|0] "unit" Vector_XXX
	SG_ SIGNAL_QUESTION_A_4 : 278|6@0- (1,0) [0|0] "unit" Vector__XXX

	SG_ NEARBY_WARNING_FLAG_3 : 268|1@0+ (1,0) [0|0] "unit" Vector__XXX
	SG_ INVALID_3 : 257|1@0+ (1,0) [0|0] "unit" Vector__XXX
	SG_ VALID_B_3 : 259|1@0+ (1,0) [0|0] "unit" Vector__XXX
	SG_ VALID_A_3 : 262|1@0+ (1,0) [0|0] "unit" Vector__XXX
	SG_ MYSTERY_RELATIVE_VELOCITY_3 : 244|13@0- (1,0) [0|0] "unit" Vector__XXX
	SG_ ABSOLUTE_DISTANCE_3 : 226|13@0+ (0.0176,0.1163) [0|0] "m" Vector__XXX
	SG_ ANGLE_3 : 215|9@0+ (0.0033,0.4509) [0|0] "radians" Vector__XXX
	SG_ BEHIND_FLAG_3 : 200|1@0+ (1,0) [0|0] "unit" Vector_XXX
	SG_ SIGNAL_QUESTION_A_3 : 206|6@0- (1,0) [0|0] "unit" Vector__XXX

	SG_ NEARBY_WARNING_FLAG_2 : 196|1@0+ (1,0) [0|0] "unit" Vector__XXX
	SG_ INVALID_2 : 185|1@0+ (1,0) [0|0] "unit" Vector__XXX
	SG_ VALID_B_2 : 187|1@0+ (1,0) [0|0] "unit" Vector__XXX
	SG_ VALID_A_2 : 190|1@0+ (1,0) [0|0] "unit" Vector__XXX
	SG_ MYSTERY_RELATIVE_VELOCITY_2 : 172|13@0- (1,0) [0|0] "unit" Vector__XXX
	SG_ ABSOLUTE_DISTANCE_2 : 154|13@0+ (0.0176,0.1163) [0|0] "m" Vector__XXX
	SG_ ANGLE_2 : 143|9@0+ (0.0033,0.4509) [0|0] "radians" Vector__XXX
	SG_ BEHIND_FLAG_2 : 128|1@0+ (1,0) [0|0] "unit" Vector_XXX
	SG_ SIGNAL_QUESTION_A_2 : 134|6@0- (1,0) [0|0] "unit" Vector__XXX

	SG_ NEARBY_WARNING_FLAG_1 : 124|1@0+ (1,0) [0|0] "unit" Vector__XXX
	SG_ INVALID_1 : 113|1@0+ (1,0) [0|0] "unit" Vector__XXX
	SG_ VALID_B_1 : 115|1@0+ (1,0) [0|0] "unit" Vector__XXX
	SG_ VALID_A_1 : 118|1@0+ (1,0) [0|0] "unit" Vector__XXX
	SG_ MYSTERY_RELATIVE_VELOCITY_1 : 100|13@0- (1,0) [0|0] "unit" Vector__XXX
	SG_ ABSOLUTE_DISTANCE_1 : 82|13@0+ (0.0176,0.1163) [0|0] "m" Vector__XXX
	SG_ ANGLE_1 : 71|9@0+ (0.0033,0.4509) [0|0] "radians" Vector__XXX
	SG_ BEHIND_FLAG_1 : 56|1@0+ (1,0) [0|0] "unit" Vector_XXX
	SG_ SIGNAL_QUESTION_A_1 : 62|6@0- (1,0) [0|0] "unit" Vector__XXX

	SG_ COUNTER : 23|8@0+ (1,0) [0|0] "unit" Vector__XXX
	SG_ CHECKSUM : 7|16@0+ (1,0) [0|0] "unit" Vector__XXX

BO_ 399 RIGHT_RADAR_5: 64 Vector__XXX
	SG_ NEARBY_WARNING_FLAG_6 : 484|1@0+ (1,0) [0|0] "unit" Vector__XXX
	SG_ INVALID_6 : 473|1@0+ (1,0) [0|0] "unit" Vector__XXX
	SG_ VALID_B_6 : 475|1@0+ (1,0) [0|0] "unit" Vector__XXX
	SG_ VALID_A_6 : 478|1@0+ (1,0) [0|0] "unit" Vector__XXX
	SG_ MYSTERY_RELATIVE_VELOCITY_6 : 460|13@0- (1,0) [0|0] "unit" Vector__XXX
	SG_ ABSOLUTE_DISTANCE_6 : 442|13@0+ (0.0176,0.1163) [0|0] "m" Vector__XXX
	SG_ ANGLE_6 : 431|9@0+ (0.0033,0.4509) [0|0] "radians" Vector__XXX
	SG_ BEHIND_FLAG_6 : 416|1@0+ (1,0) [0|0] "unit" Vector_XXX
	SG_ SIGNAL_QUESTION_A_6 : 422|6@0- (1,0) [0|0] "unit" Vector__XXX

	SG_ NEARBY_WARNING_FLAG_5 : 412|1@0+ (1,0) [0|0] "unit" Vector__XXX
	SG_ INVALID_5 : 401|1@0+ (1,0) [0|0] "unit" Vector__XXX
	SG_ VALID_B_5 : 403|1@0+ (1,0) [0|0] "unit" Vector__XXX
	SG_ VALID_A_5 : 406|1@0+ (1,0) [0|0] "unit" Vector__XXX
	SG_ MYSTERY_RELATIVE_VELOCITY_5 : 388|13@0- (1,0) [0|0] "unit" Vector__XXX
	SG_ ABSOLUTE_DISTANCE_5 : 370|13@0+ (0.0176,0.1163) [0|0] "m" Vector__XXX
	SG_ ANGLE_5 : 359|9@0+ (0.0033,0.4509) [0|0] "radians" Vector__XXX
	SG_ BEHIND_FLAG_5 : 344|1@0+ (1,0) [0|0] "unit" Vector_XXX
	SG_ SIGNAL_QUESTION_A_5 : 350|6@0- (1,0) [0|0] "unit" Vector__XXX

	SG_ NEARBY_WARNING_FLAG_4 : 340|1@0+ (1,0) [0|0] "unit" Vector__XXX
	SG_ INVALID_4 : 329|1@0+ (1,0) [0|0] "unit" Vector__XXX
	SG_ VALID_B_4 : 331|1@0+ (1,0) [0|0] "unit" Vector__XXX
	SG_ VALID_A_4 : 334|1@0+ (1,0) [0|0] "unit" Vector__XXX
	SG_ MYSTERY_RELATIVE_VELOCITY_4 : 316|13@0- (1,0) [0|0] "unit" Vector__XXX
	SG_ ABSOLUTE_DISTANCE_4 : 298|13@0+ (0.0176,0.1163) [0|0] "m" Vector__XXX
	SG_ ANGLE_4 : 287|9@0+ (0.0033,0.4509) [0|0] "radians" Vector__XXX
	SG_ BEHIND_FLAG_4 : 272|1@0+ (1,0) [0|0] "unit" Vector_XXX
	SG_ SIGNAL_QUESTION_A_4 : 278|6@0- (1,0) [0|0] "unit" Vector__XXX

	SG_ NEARBY_WARNING_FLAG_3 : 268|1@0+ (1,0) [0|0] "unit" Vector__XXX
	SG_ INVALID_3 : 257|1@0+ (1,0) [0|0] "unit" Vector__XXX
	SG_ VALID_B_3 : 259|1@0+ (1,0) [0|0] "unit" Vector__XXX
	SG_ VALID_A_3 : 262|1@0+ (1,0) [0|0] "unit" Vector__XXX
	SG_ MYSTERY_RELATIVE_VELOCITY_3 : 244|13@0- (1,0) [0|0] "unit" Vector__XXX
	SG_ ABSOLUTE_DISTANCE_3 : 226|13@0+ (0.0176,0.1163) [0|0] "m" Vector__XXX
	SG_ ANGLE_3 : 215|9@0+ (0.0033,0.4509) [0|0] "radians" Vector__XXX
	SG_ BEHIND_FLAG_3 : 200|1@0+ (1,0) [0|0] "unit" Vector_XXX
	SG_ SIGNAL_QUESTION_A_3 : 206|6@0- (1,0) [0|0] "unit" Vector__XXX

	SG_ NEARBY_WARNING_FLAG_2 : 196|1@0+ (1,0) [0|0] "unit" Vector__XXX
	SG_ INVALID_2 : 185|1@0+ (1,0) [0|0] "unit" Vector__XXX
	SG_ VALID_B_2 : 187|1@0+ (1,0) [0|0] "unit" Vector__XXX
	SG_ VALID_A_2 : 190|1@0+ (1,0) [0|0] "unit" Vector__XXX
	SG_ MYSTERY_RELATIVE_VELOCITY_2 : 172|13@0- (1,0) [0|0] "unit" Vector__XXX
	SG_ ABSOLUTE_DISTANCE_2 : 154|13@0+ (0.0176,0.1163) [0|0] "m" Vector__XXX
	SG_ ANGLE_2 : 143|9@0+ (0.0033,0.4509) [0|0] "radians" Vector__XXX
	SG_ BEHIND_FLAG_2 : 128|1@0+ (1,0) [0|0] "unit" Vector_XXX
	SG_ SIGNAL_QUESTION_A_2 : 134|6@0- (1,0) [0|0] "unit" Vector__XXX

	SG_ NEARBY_WARNING_FLAG_1 : 124|1@0+ (1,0) [0|0] "unit" Vector__XXX
	SG_ INVALID_1 : 113|1@0+ (1,0) [0|0] "unit" Vector__XXX
	SG_ VALID_B_1 : 115|1@0+ (1,0) [0|0] "unit" Vector__XXX
	SG_ VALID_A_1 : 118|1@0+ (1,0) [0|0] "unit" Vector__XXX
	SG_ MYSTERY_RELATIVE_VELOCITY_1 : 100|13@0- (1,0) [0|0] "unit" Vector__XXX
	SG_ ABSOLUTE_DISTANCE_1 : 82|13@0+ (0.0176,0.1163) [0|0] "m" Vector__XXX
	SG_ ANGLE_1 : 71|9@0+ (0.0033,0.4509) [0|0] "radians" Vector__XXX
	SG_ BEHIND_FLAG_1 : 56|1@0+ (1,0) [0|0] "unit" Vector_XXX
	SG_ SIGNAL_QUESTION_A_1 : 62|6@0- (1,0) [0|0] "unit" Vector__XXX

	SG_ COUNTER : 23|8@0+ (1,0) [0|0] "unit" Vector__XXX
	SG_ CHECKSUM : 7|16@0+ (1,0) [0|0] "unit" Vector__XXX

BO_ 405 LEFT_RADAR_6: 64 Vector__XXX
	SG_ NEARBY_WARNING_FLAG_6 : 484|1@0+ (1,0) [0|0] "unit" Vector__XXX
	SG_ INVALID_6 : 473|1@0+ (1,0) [0|0] "unit" Vector__XXX
	SG_ VALID_B_6 : 475|1@0+ (1,0) [0|0] "unit" Vector__XXX
	SG_ VALID_A_6 : 478|1@0+ (1,0) [0|0] "unit" Vector__XXX
	SG_ MYSTERY_RELATIVE_VELOCITY_6 : 460|13@0- (1,0) [0|0] "unit" Vector__XXX
	SG_ ABSOLUTE_DISTANCE_6 : 442|13@0+ (0.0176,0.1163) [0|0] "m" Vector__XXX
	SG_ ANGLE_6 : 431|9@0+ (0.0033,0.4509) [0|0] "radians" Vector__XXX
	SG_ BEHIND_FLAG_6 : 416|1@0+ (1,0) [0|0] "unit" Vector_XXX
	SG_ SIGNAL_QUESTION_A_6 : 422|6@0- (1,0) [0|0] "unit" Vector__XXX

	SG_ NEARBY_WARNING_FLAG_5 : 412|1@0+ (1,0) [0|0] "unit" Vector__XXX
	SG_ INVALID_5 : 401|1@0+ (1,0) [0|0] "unit" Vector__XXX
	SG_ VALID_B_5 : 403|1@0+ (1,0) [0|0] "unit" Vector__XXX
	SG_ VALID_A_5 : 406|1@0+ (1,0) [0|0] "unit" Vector__XXX
	SG_ MYSTERY_RELATIVE_VELOCITY_5 : 388|13@0- (1,0) [0|0] "unit" Vector__XXX
	SG_ ABSOLUTE_DISTANCE_5 : 370|13@0+ (0.0176,0.1163) [0|0] "m" Vector__XXX
	SG_ ANGLE_5 : 359|9@0+ (0.0033,0.4509) [0|0] "radians" Vector__XXX
	SG_ BEHIND_FLAG_5 : 344|1@0+ (1,0) [0|0] "unit" Vector_XXX
	SG_ SIGNAL_QUESTION_A_5 : 350|6@0- (1,0) [0|0] "unit" Vector__XXX

	SG_ NEARBY_WARNING_FLAG_4 : 340|1@0+ (1,0) [0|0] "unit" Vector__XXX
	SG_ INVALID_4 : 329|1@0+ (1,0) [0|0] "unit" Vector__XXX
	SG_ VALID_B_4 : 331|1@0+ (1,0) [0|0] "unit" Vector__XXX
	SG_ VALID_A_4 : 334|1@0+ (1,0) [0|0] "unit" Vector__XXX
	SG_ MYSTERY_RELATIVE_VELOCITY_4 : 316|13@0- (1,0) [0|0] "unit" Vector__XXX
	SG_ ABSOLUTE_DISTANCE_4 : 298|13@0+ (0.0176,0.1163) [0|0] "m" Vector__XXX
	SG_ ANGLE_4 : 287|9@0+ (0.0033,0.4509) [0|0] "radians" Vector__XXX
	SG_ BEHIND_FLAG_4 : 272|1@0+ (1,0) [0|0] "unit" Vector_XXX
	SG_ SIGNAL_QUESTION_A_4 : 278|6@0- (1,0) [0|0] "unit" Vector__XXX

	SG_ NEARBY_WARNING_FLAG_3 : 268|1@0+ (1,0) [0|0] "unit" Vector__XXX
	SG_ INVALID_3 : 257|1@0+ (1,0) [0|0] "unit" Vector__XXX
	SG_ VALID_B_3 : 259|1@0+ (1,0) [0|0] "unit" Vector__XXX
	SG_ VALID_A_3 : 262|1@0+ (1,0) [0|0] "unit" Vector__XXX
	SG_ MYSTERY_RELATIVE_VELOCITY_3 : 244|13@0- (1,0) [0|0] "unit" Vector__XXX
	SG_ ABSOLUTE_DISTANCE_3 : 226|13@0+ (0.0176,0.1163) [0|0] "m" Vector__XXX
	SG_ ANGLE_3 : 215|9@0+ (0.0033,0.4509) [0|0] "radians" Vector__XXX
	SG_ BEHIND_FLAG_3 : 200|1@0+ (1,0) [0|0] "unit" Vector_XXX
	SG_ SIGNAL_QUESTION_A_3 : 206|6@0- (1,0) [0|0] "unit" Vector__XXX

	SG_ NEARBY_WARNING_FLAG_2 : 196|1@0+ (1,0) [0|0] "unit" Vector__XXX
	SG_ INVALID_2 : 185|1@0+ (1,0) [0|0] "unit" Vector__XXX
	SG_ VALID_B_2 : 187|1@0+ (1,0) [0|0] "unit" Vector__XXX
	SG_ VALID_A_2 : 190|1@0+ (1,0) [0|0] "unit" Vector__XXX
	SG_ MYSTERY_RELATIVE_VELOCITY_2 : 172|13@0- (1,0) [0|0] "unit" Vector__XXX
	SG_ ABSOLUTE_DISTANCE_2 : 154|13@0+ (0.0176,0.1163) [0|0] "m" Vector__XXX
	SG_ ANGLE_2 : 143|9@0+ (0.0033,0.4509) [0|0] "radians" Vector__XXX
	SG_ BEHIND_FLAG_2 : 128|1@0+ (1,0) [0|0] "unit" Vector_XXX
	SG_ SIGNAL_QUESTION_A_2 : 134|6@0- (1,0) [0|0] "unit" Vector__XXX

	SG_ NEARBY_WARNING_FLAG_1 : 124|1@0+ (1,0) [0|0] "unit" Vector__XXX
	SG_ INVALID_1 : 113|1@0+ (1,0) [0|0] "unit" Vector__XXX
	SG_ VALID_B_1 : 115|1@0+ (1,0) [0|0] "unit" Vector__XXX
	SG_ VALID_A_1 : 118|1@0+ (1,0) [0|0] "unit" Vector__XXX
	SG_ MYSTERY_RELATIVE_VELOCITY_1 : 100|13@0- (1,0) [0|0] "unit" Vector__XXX
	SG_ ABSOLUTE_DISTANCE_1 : 82|13@0+ (0.0176,0.1163) [0|0] "m" Vector__XXX
	SG_ ANGLE_1 : 71|9@0+ (0.0033,0.4509) [0|0] "radians" Vector__XXX
	SG_ BEHIND_FLAG_1 : 56|1@0+ (1,0) [0|0] "unit" Vector_XXX
	SG_ SIGNAL_QUESTION_A_1 : 62|6@0- (1,0) [0|0] "unit" Vector__XXX

	SG_ COUNTER : 23|8@0+ (1,0) [0|0] "unit" Vector__XXX
	SG_ CHECKSUM : 7|16@0+ (1,0) [0|0] "unit" Vector__XXX

BO_ 407 RIGHT_RADAR_6: 64 Vector__XXX
	SG_ NEARBY_WARNING_FLAG_6 : 484|1@0+ (1,0) [0|0] "unit" Vector__XXX
	SG_ INVALID_6 : 473|1@0+ (1,0) [0|0] "unit" Vector__XXX
	SG_ VALID_B_6 : 475|1@0+ (1,0) [0|0] "unit" Vector__XXX
	SG_ VALID_A_6 : 478|1@0+ (1,0) [0|0] "unit" Vector__XXX
	SG_ MYSTERY_RELATIVE_VELOCITY_6 : 460|13@0- (1,0) [0|0] "unit" Vector__XXX
	SG_ ABSOLUTE_DISTANCE_6 : 442|13@0+ (0.0176,0.1163) [0|0] "m" Vector__XXX
	SG_ ANGLE_6 : 431|9@0+ (0.0033,0.4509) [0|0] "radians" Vector__XXX
	SG_ BEHIND_FLAG_6 : 416|1@0+ (1,0) [0|0] "unit" Vector_XXX
	SG_ SIGNAL_QUESTION_A_6 : 422|6@0- (1,0) [0|0] "unit" Vector__XXX

	SG_ NEARBY_WARNING_FLAG_5 : 412|1@0+ (1,0) [0|0] "unit" Vector__XXX
	SG_ INVALID_5 : 401|1@0+ (1,0) [0|0] "unit" Vector__XXX
	SG_ VALID_B_5 : 403|1@0+ (1,0) [0|0] "unit" Vector__XXX
	SG_ VALID_A_5 : 406|1@0+ (1,0) [0|0] "unit" Vector__XXX
	SG_ MYSTERY_RELATIVE_VELOCITY_5 : 388|13@0- (1,0) [0|0] "unit" Vector__XXX
	SG_ ABSOLUTE_DISTANCE_5 : 370|13@0+ (0.0176,0.1163) [0|0] "m" Vector__XXX
	SG_ ANGLE_5 : 359|9@0+ (0.0033,0.4509) [0|0] "radians" Vector__XXX
	SG_ BEHIND_FLAG_5 : 344|1@0+ (1,0) [0|0] "unit" Vector_XXX
	SG_ SIGNAL_QUESTION_A_5 : 350|6@0- (1,0) [0|0] "unit" Vector__XXX

	SG_ NEARBY_WARNING_FLAG_4 : 340|1@0+ (1,0) [0|0] "unit" Vector__XXX
	SG_ INVALID_4 : 329|1@0+ (1,0) [0|0] "unit" Vector__XXX
	SG_ VALID_B_4 : 331|1@0+ (1,0) [0|0] "unit" Vector__XXX
	SG_ VALID_A_4 : 334|1@0+ (1,0) [0|0] "unit" Vector__XXX
	SG_ MYSTERY_RELATIVE_VELOCITY_4 : 316|13@0- (1,0) [0|0] "unit" Vector__XXX
	SG_ ABSOLUTE_DISTANCE_4 : 298|13@0+ (0.0176,0.1163) [0|0] "m" Vector__XXX
	SG_ ANGLE_4 : 287|9@0+ (0.0033,0.4509) [0|0] "radians" Vector__XXX
	SG_ BEHIND_FLAG_4 : 272|1@0+ (1,0) [0|0] "unit" Vector_XXX
	SG_ SIGNAL_QUESTION_A_4 : 278|6@0- (1,0) [0|0] "unit" Vector__XXX

	SG_ NEARBY_WARNING_FLAG_3 : 268|1@0+ (1,0) [0|0] "unit" Vector__XXX
	SG_ INVALID_3 : 257|1@0+ (1,0) [0|0] "unit" Vector__XXX
	SG_ VALID_B_3 : 259|1@0+ (1,0) [0|0] "unit" Vector__XXX
	SG_ VALID_A_3 : 262|1@0+ (1,0) [0|0] "unit" Vector__XXX
	SG_ MYSTERY_RELATIVE_VELOCITY_3 : 244|13@0- (1,0) [0|0] "unit" Vector__XXX
	SG_ ABSOLUTE_DISTANCE_3 : 226|13@0+ (0.0176,0.1163) [0|0] "m" Vector__XXX
	SG_ ANGLE_3 : 215|9@0+ (0.0033,0.4509) [0|0] "radians" Vector__XXX
	SG_ BEHIND_FLAG_3 : 200|1@0+ (1,0) [0|0] "unit" Vector_XXX
	SG_ SIGNAL_QUESTION_A_3 : 206|6@0- (1,0) [0|0] "unit" Vector__XXX

	SG_ NEARBY_WARNING_FLAG_2 : 196|1@0+ (1,0) [0|0] "unit" Vector__XXX
	SG_ INVALID_2 : 185|1@0+ (1,0) [0|0] "unit" Vector__XXX
	SG_ VALID_B_2 : 187|1@0+ (1,0) [0|0] "unit" Vector__XXX
	SG_ VALID_A_2 : 190|1@0+ (1,0) [0|0] "unit" Vector__XXX
	SG_ MYSTERY_RELATIVE_VELOCITY_2 : 172|13@0- (1,0) [0|0] "unit" Vector__XXX
	SG_ ABSOLUTE_DISTANCE_2 : 154|13@0+ (0.0176,0.1163) [0|0] "m" Vector__XXX
	SG_ ANGLE_2 : 143|9@0+ (0.0033,0.4509) [0|0] "radians" Vector__XXX
	SG_ BEHIND_FLAG_2 : 128|1@0+ (1,0) [0|0] "unit" Vector_XXX
	SG_ SIGNAL_QUESTION_A_2 : 134|6@0- (1,0) [0|0] "unit" Vector__XXX

	SG_ NEARBY_WARNING_FLAG_1 : 124|1@0+ (1,0) [0|0] "unit" Vector__XXX
	SG_ INVALID_1 : 113|1@0+ (1,0) [0|0] "unit" Vector__XXX
	SG_ VALID_B_1 : 115|1@0+ (1,0) [0|0] "unit" Vector__XXX
	SG_ VALID_A_1 : 118|1@0+ (1,0) [0|0] "unit" Vector__XXX
	SG_ MYSTERY_RELATIVE_VELOCITY_1 : 100|13@0- (1,0) [0|0] "unit" Vector__XXX
	SG_ ABSOLUTE_DISTANCE_1 : 82|13@0+ (0.0176,0.1163) [0|0] "m" Vector__XXX
	SG_ ANGLE_1 : 71|9@0+ (0.0033,0.4509) [0|0] "radians" Vector__XXX
	SG_ BEHIND_FLAG_1 : 56|1@0+ (1,0) [0|0] "unit" Vector_XXX
	SG_ SIGNAL_QUESTION_A_1 : 62|6@0- (1,0) [0|0] "unit" Vector__XXX

	SG_ COUNTER : 23|8@0+ (1,0) [0|0] "unit" Vector__XXX
	SG_ CHECKSUM : 7|16@0+ (1,0) [0|0] "unit" Vector__XXX

BO_ 411 LEFT_RADAR_7: 64 Vector__XXX
	SG_ NEARBY_WARNING_FLAG_6 : 484|1@0+ (1,0) [0|0] "unit" Vector__XXX
	SG_ INVALID_6 : 473|1@0+ (1,0) [0|0] "unit" Vector__XXX
	SG_ VALID_B_6 : 475|1@0+ (1,0) [0|0] "unit" Vector__XXX
	SG_ VALID_A_6 : 478|1@0+ (1,0) [0|0] "unit" Vector__XXX
	SG_ MYSTERY_RELATIVE_VELOCITY_6 : 460|13@0- (1,0) [0|0] "unit" Vector__XXX
	SG_ ABSOLUTE_DISTANCE_6 : 442|13@0+ (0.0176,0.1163) [0|0] "m" Vector__XXX
	SG_ ANGLE_6 : 431|9@0+ (0.0033,0.4509) [0|0] "radians" Vector__XXX
	SG_ BEHIND_FLAG_6 : 416|1@0+ (1,0) [0|0] "unit" Vector_XXX
	SG_ SIGNAL_QUESTION_A_6 : 422|6@0- (1,0) [0|0] "unit" Vector__XXX

	SG_ NEARBY_WARNING_FLAG_5 : 412|1@0+ (1,0) [0|0] "unit" Vector__XXX
	SG_ INVALID_5 : 401|1@0+ (1,0) [0|0] "unit" Vector__XXX
	SG_ VALID_B_5 : 403|1@0+ (1,0) [0|0] "unit" Vector__XXX
	SG_ VALID_A_5 : 406|1@0+ (1,0) [0|0] "unit" Vector__XXX
	SG_ MYSTERY_RELATIVE_VELOCITY_5 : 388|13@0- (1,0) [0|0] "unit" Vector__XXX
	SG_ ABSOLUTE_DISTANCE_5 : 370|13@0+ (0.0176,0.1163) [0|0] "m" Vector__XXX
	SG_ ANGLE_5 : 359|9@0+ (0.0033,0.4509) [0|0] "radians" Vector__XXX
	SG_ BEHIND_FLAG_5 : 344|1@0+ (1,0) [0|0] "unit" Vector_XXX
	SG_ SIGNAL_QUESTION_A_5 : 350|6@0- (1,0) [0|0] "unit" Vector__XXX

	SG_ NEARBY_WARNING_FLAG_4 : 340|1@0+ (1,0) [0|0] "unit" Vector__XXX
	SG_ INVALID_4 : 329|1@0+ (1,0) [0|0] "unit" Vector__XXX
	SG_ VALID_B_4 : 331|1@0+ (1,0) [0|0] "unit" Vector__XXX
	SG_ VALID_A_4 : 334|1@0+ (1,0) [0|0] "unit" Vector__XXX
	SG_ MYSTERY_RELATIVE_VELOCITY_4 : 316|13@0- (1,0) [0|0] "unit" Vector__XXX
	SG_ ABSOLUTE_DISTANCE_4 : 298|13@0+ (0.0176,0.1163) [0|0] "m" Vector__XXX
	SG_ ANGLE_4 : 287|9@0+ (0.0033,0.4509) [0|0] "radians" Vector__XXX
	SG_ BEHIND_FLAG_4 : 272|1@0+ (1,0) [0|0] "unit" Vector_XXX
	SG_ SIGNAL_QUESTION_A_4 : 278|6@0- (1,0) [0|0] "unit" Vector__XXX

	SG_ NEARBY_WARNING_FLAG_3 : 268|1@0+ (1,0) [0|0] "unit" Vector__XXX
	SG_ INVALID_3 : 257|1@0+ (1,0) [0|0] "unit" Vector__XXX
	SG_ VALID_B_3 : 259|1@0+ (1,0) [0|0] "unit" Vector__XXX
	SG_ VALID_A_3 : 262|1@0+ (1,0) [0|0] "unit" Vector__XXX
	SG_ MYSTERY_RELATIVE_VELOCITY_3 : 244|13@0- (1,0) [0|0] "unit" Vector__XXX
	SG_ ABSOLUTE_DISTANCE_3 : 226|13@0+ (0.0176,0.1163) [0|0] "m" Vector__XXX
	SG_ ANGLE_3 : 215|9@0+ (0.0033,0.4509) [0|0] "radians" Vector__XXX
	SG_ BEHIND_FLAG_3 : 200|1@0+ (1,0) [0|0] "unit" Vector_XXX
	SG_ SIGNAL_QUESTION_A_3 : 206|6@0- (1,0) [0|0] "unit" Vector__XXX

	SG_ NEARBY_WARNING_FLAG_2 : 196|1@0+ (1,0) [0|0] "unit" Vector__XXX
	SG_ INVALID_2 : 185|1@0+ (1,0) [0|0] "unit" Vector__XXX
	SG_ VALID_B_2 : 187|1@0+ (1,0) [0|0] "unit" Vector__XXX
	SG_ VALID_A_2 : 190|1@0+ (1,0) [0|0] "unit" Vector__XXX
	SG_ MYSTERY_RELATIVE_VELOCITY_2 : 172|13@0- (1,0) [0|0] "unit" Vector__XXX
	SG_ ABSOLUTE_DISTANCE_2 : 154|13@0+ (0.0176,0.1163) [0|0] "m" Vector__XXX
	SG_ ANGLE_2 : 143|9@0+ (0.0033,0.4509) [0|0] "radians" Vector__XXX
	SG_ BEHIND_FLAG_2 : 128|1@0+ (1,0) [0|0] "unit" Vector_XXX
	SG_ SIGNAL_QUESTION_A_2 : 134|6@0- (1,0) [0|0] "unit" Vector__XXX

	SG_ NEARBY_WARNING_FLAG_1 : 124|1@0+ (1,0) [0|0] "unit" Vector__XXX
	SG_ INVALID_1 : 113|1@0+ (1,0) [0|0] "unit" Vector__XXX
	SG_ VALID_B_1 : 115|1@0+ (1,0) [0|0] "unit" Vector__XXX
	SG_ VALID_A_1 : 118|1@0+ (1,0) [0|0] "unit" Vector__XXX
	SG_ MYSTERY_RELATIVE_VELOCITY_1 : 100|13@0- (1,0) [0|0] "unit" Vector__XXX
	SG_ ABSOLUTE_DISTANCE_1 : 82|13@0+ (0.0176,0.1163) [0|0] "m" Vector__XXX
	SG_ ANGLE_1 : 71|9@0+ (0.0033,0.4509) [0|0] "radians" Vector__XXX
	SG_ BEHIND_FLAG_1 : 56|1@0+ (1,0) [0|0] "unit" Vector_XXX
	SG_ SIGNAL_QUESTION_A_1 : 62|6@0- (1,0) [0|0] "unit" Vector__XXX

	SG_ COUNTER : 23|8@0+ (1,0) [0|0] "unit" Vector__XXX
	SG_ CHECKSUM : 7|16@0+ (1,0) [0|0] "unit" Vector__XXX

BO_ 412 RIGHT_RADAR_7: 64 Vector__XXX
	SG_ NEARBY_WARNING_FLAG_6 : 484|1@0+ (1,0) [0|0] "unit" Vector__XXX
	SG_ INVALID_6 : 473|1@0+ (1,0) [0|0] "unit" Vector__XXX
	SG_ VALID_B_6 : 475|1@0+ (1,0) [0|0] "unit" Vector__XXX
	SG_ VALID_A_6 : 478|1@0+ (1,0) [0|0] "unit" Vector__XXX
	SG_ MYSTERY_RELATIVE_VELOCITY_6 : 460|13@0- (1,0) [0|0] "unit" Vector__XXX
	SG_ ABSOLUTE_DISTANCE_6 : 442|13@0+ (0.0176,0.1163) [0|0] "m" Vector__XXX
	SG_ ANGLE_6 : 431|9@0+ (0.0033,0.4509) [0|0] "radians" Vector__XXX
	SG_ BEHIND_FLAG_6 : 416|1@0+ (1,0) [0|0] "unit" Vector_XXX
	SG_ SIGNAL_QUESTION_A_6 : 422|6@0- (1,0) [0|0] "unit" Vector__XXX

	SG_ NEARBY_WARNING_FLAG_5 : 412|1@0+ (1,0) [0|0] "unit" Vector__XXX
	SG_ INVALID_5 : 401|1@0+ (1,0) [0|0] "unit" Vector__XXX
	SG_ VALID_B_5 : 403|1@0+ (1,0) [0|0] "unit" Vector__XXX
	SG_ VALID_A_5 : 406|1@0+ (1,0) [0|0] "unit" Vector__XXX
	SG_ MYSTERY_RELATIVE_VELOCITY_5 : 388|13@0- (1,0) [0|0] "unit" Vector__XXX
	SG_ ABSOLUTE_DISTANCE_5 : 370|13@0+ (0.0176,0.1163) [0|0] "m" Vector__XXX
	SG_ ANGLE_5 : 359|9@0+ (0.0033,0.4509) [0|0] "radians" Vector__XXX
	SG_ BEHIND_FLAG_5 : 344|1@0+ (1,0) [0|0] "unit" Vector_XXX
	SG_ SIGNAL_QUESTION_A_5 : 350|6@0- (1,0) [0|0] "unit" Vector__XXX

	SG_ NEARBY_WARNING_FLAG_4 : 340|1@0+ (1,0) [0|0] "unit" Vector__XXX
	SG_ INVALID_4 : 329|1@0+ (1,0) [0|0] "unit" Vector__XXX
	SG_ VALID_B_4 : 331|1@0+ (1,0) [0|0] "unit" Vector__XXX
	SG_ VALID_A_4 : 334|1@0+ (1,0) [0|0] "unit" Vector__XXX
	SG_ MYSTERY_RELATIVE_VELOCITY_4 : 316|13@0- (1,0) [0|0] "unit" Vector__XXX
	SG_ ABSOLUTE_DISTANCE_4 : 298|13@0+ (0.0176,0.1163) [0|0] "m" Vector__XXX
	SG_ ANGLE_4 : 287|9@0+ (0.0033,0.4509) [0|0] "radians" Vector__XXX
	SG_ BEHIND_FLAG_4 : 272|1@0+ (1,0) [0|0] "unit" Vector_XXX
	SG_ SIGNAL_QUESTION_A_4 : 278|6@0- (1,0) [0|0] "unit" Vector__XXX

	SG_ NEARBY_WARNING_FLAG_3 : 268|1@0+ (1,0) [0|0] "unit" Vector__XXX
	SG_ INVALID_3 : 257|1@0+ (1,0) [0|0] "unit" Vector__XXX
	SG_ VALID_B_3 : 259|1@0+ (1,0) [0|0] "unit" Vector__XXX
	SG_ VALID_A_3 : 262|1@0+ (1,0) [0|0] "unit" Vector__XXX
	SG_ MYSTERY_RELATIVE_VELOCITY_3 : 244|13@0- (1,0) [0|0] "unit" Vector__XXX
	SG_ ABSOLUTE_DISTANCE_3 : 226|13@0+ (0.0176,0.1163) [0|0] "m" Vector__XXX
	SG_ ANGLE_3 : 215|9@0+ (0.0033,0.4509) [0|0] "radians" Vector__XXX
	SG_ BEHIND_FLAG_3 : 200|1@0+ (1,0) [0|0] "unit" Vector_XXX
	SG_ SIGNAL_QUESTION_A_3 : 206|6@0- (1,0) [0|0] "unit" Vector__XXX

	SG_ NEARBY_WARNING_FLAG_2 : 196|1@0+ (1,0) [0|0] "unit" Vector__XXX
	SG_ INVALID_2 : 185|1@0+ (1,0) [0|0] "unit" Vector__XXX
	SG_ VALID_B_2 : 187|1@0+ (1,0) [0|0] "unit" Vector__XXX
	SG_ VALID_A_2 : 190|1@0+ (1,0) [0|0] "unit" Vector__XXX
	SG_ MYSTERY_RELATIVE_VELOCITY_2 : 172|13@0- (1,0) [0|0] "unit" Vector__XXX
	SG_ ABSOLUTE_DISTANCE_2 : 154|13@0+ (0.0176,0.1163) [0|0] "m" Vector__XXX
	SG_ ANGLE_2 : 143|9@0+ (0.0033,0.4509) [0|0] "radians" Vector__XXX
	SG_ BEHIND_FLAG_2 : 128|1@0+ (1,0) [0|0] "unit" Vector_XXX
	SG_ SIGNAL_QUESTION_A_2 : 134|6@0- (1,0) [0|0] "unit" Vector__XXX

	SG_ NEARBY_WARNING_FLAG_1 : 124|1@0+ (1,0) [0|0] "unit" Vector__XXX
	SG_ INVALID_1 : 113|1@0+ (1,0) [0|0] "unit" Vector__XXX
	SG_ VALID_B_1 : 115|1@0+ (1,0) [0|0] "unit" Vector__XXX
	SG_ VALID_A_1 : 118|1@0+ (1,0) [0|0] "unit" Vector__XXX
	SG_ MYSTERY_RELATIVE_VELOCITY_1 : 100|13@0- (1,0) [0|0] "unit" Vector__XXX
	SG_ ABSOLUTE_DISTANCE_1 : 82|13@0+ (0.0176,0.1163) [0|0] "m" Vector__XXX
	SG_ ANGLE_1 : 71|9@0+ (0.0033,0.4509) [0|0] "radians" Vector__XXX
	SG_ BEHIND_FLAG_1 : 56|1@0+ (1,0) [0|0] "unit" Vector_XXX
	SG_ SIGNAL_QUESTION_A_1 : 62|6@0- (1,0) [0|0] "unit" Vector__XXX

	SG_ COUNTER : 23|8@0+ (1,0) [0|0] "unit" Vector__XXX
	SG_ CHECKSUM : 7|16@0+ (1,0) [0|0] "unit" Vector__XXX

BO_ 415 LEFT_RADAR_8: 64 Vector__XXX
	SG_ NEARBY_WARNING_FLAG_6 : 484|1@0+ (1,0) [0|0] "unit" Vector__XXX
	SG_ INVALID_6 : 473|1@0+ (1,0) [0|0] "unit" Vector__XXX
	SG_ VALID_B_6 : 475|1@0+ (1,0) [0|0] "unit" Vector__XXX
	SG_ VALID_A_6 : 478|1@0+ (1,0) [0|0] "unit" Vector__XXX
	SG_ MYSTERY_RELATIVE_VELOCITY_6 : 460|13@0- (1,0) [0|0] "unit" Vector__XXX
	SG_ ABSOLUTE_DISTANCE_6 : 442|13@0+ (0.0176,0.1163) [0|0] "m" Vector__XXX
	SG_ ANGLE_6 : 431|9@0+ (0.0033,0.4509) [0|0] "radians" Vector__XXX
	SG_ BEHIND_FLAG_6 : 416|1@0+ (1,0) [0|0] "unit" Vector_XXX
	SG_ SIGNAL_QUESTION_A_6 : 422|6@0- (1,0) [0|0] "unit" Vector__XXX

	SG_ NEARBY_WARNING_FLAG_5 : 412|1@0+ (1,0) [0|0] "unit" Vector__XXX
	SG_ INVALID_5 : 401|1@0+ (1,0) [0|0] "unit" Vector__XXX
	SG_ VALID_B_5 : 403|1@0+ (1,0) [0|0] "unit" Vector__XXX
	SG_ VALID_A_5 : 406|1@0+ (1,0) [0|0] "unit" Vector__XXX
	SG_ MYSTERY_RELATIVE_VELOCITY_5 : 388|13@0- (1,0) [0|0] "unit" Vector__XXX
	SG_ ABSOLUTE_DISTANCE_5 : 370|13@0+ (0.0176,0.1163) [0|0] "m" Vector__XXX
	SG_ ANGLE_5 : 359|9@0+ (0.0033,0.4509) [0|0] "radians" Vector__XXX
	SG_ BEHIND_FLAG_5 : 344|1@0+ (1,0) [0|0] "unit" Vector_XXX
	SG_ SIGNAL_QUESTION_A_5 : 350|6@0- (1,0) [0|0] "unit" Vector__XXX

	SG_ NEARBY_WARNING_FLAG_4 : 340|1@0+ (1,0) [0|0] "unit" Vector__XXX
	SG_ INVALID_4 : 329|1@0+ (1,0) [0|0] "unit" Vector__XXX
	SG_ VALID_B_4 : 331|1@0+ (1,0) [0|0] "unit" Vector__XXX
	SG_ VALID_A_4 : 334|1@0+ (1,0) [0|0] "unit" Vector__XXX
	SG_ MYSTERY_RELATIVE_VELOCITY_4 : 316|13@0- (1,0) [0|0] "unit" Vector__XXX
	SG_ ABSOLUTE_DISTANCE_4 : 298|13@0+ (0.0176,0.1163) [0|0] "m" Vector__XXX
	SG_ ANGLE_4 : 287|9@0+ (0.0033,0.4509) [0|0] "radians" Vector__XXX
	SG_ BEHIND_FLAG_4 : 272|1@0+ (1,0) [0|0] "unit" Vector_XXX
	SG_ SIGNAL_QUESTION_A_4 : 278|6@0- (1,0) [0|0] "unit" Vector__XXX

	SG_ NEARBY_WARNING_FLAG_3 : 268|1@0+ (1,0) [0|0] "unit" Vector__XXX
	SG_ INVALID_3 : 257|1@0+ (1,0) [0|0] "unit" Vector__XXX
	SG_ VALID_B_3 : 259|1@0+ (1,0) [0|0] "unit" Vector__XXX
	SG_ VALID_A_3 : 262|1@0+ (1,0) [0|0] "unit" Vector__XXX
	SG_ MYSTERY_RELATIVE_VELOCITY_3 : 244|13@0- (1,0) [0|0] "unit" Vector__XXX
	SG_ ABSOLUTE_DISTANCE_3 : 226|13@0+ (0.0176,0.1163) [0|0] "m" Vector__XXX
	SG_ ANGLE_3 : 215|9@0+ (0.0033,0.4509) [0|0] "radians" Vector__XXX
	SG_ BEHIND_FLAG_3 : 200|1@0+ (1,0) [0|0] "unit" Vector_XXX
	SG_ SIGNAL_QUESTION_A_3 : 206|6@0- (1,0) [0|0] "unit" Vector__XXX

	SG_ NEARBY_WARNING_FLAG_2 : 196|1@0+ (1,0) [0|0] "unit" Vector__XXX
	SG_ INVALID_2 : 185|1@0+ (1,0) [0|0] "unit" Vector__XXX
	SG_ VALID_B_2 : 187|1@0+ (1,0) [0|0] "unit" Vector__XXX
	SG_ VALID_A_2 : 190|1@0+ (1,0) [0|0] "unit" Vector__XXX
	SG_ MYSTERY_RELATIVE_VELOCITY_2 : 172|13@0- (1,0) [0|0] "unit" Vector__XXX
	SG_ ABSOLUTE_DISTANCE_2 : 154|13@0+ (0.0176,0.1163) [0|0] "m" Vector__XXX
	SG_ ANGLE_2 : 143|9@0+ (0.0033,0.4509) [0|0] "radians" Vector__XXX
	SG_ BEHIND_FLAG_2 : 128|1@0+ (1,0) [0|0] "unit" Vector_XXX
	SG_ SIGNAL_QUESTION_A_2 : 134|6@0- (1,0) [0|0] "unit" Vector__XXX

	SG_ NEARBY_WARNING_FLAG_1 : 124|1@0+ (1,0) [0|0] "unit" Vector__XXX
	SG_ INVALID_1 : 113|1@0+ (1,0) [0|0] "unit" Vector__XXX
	SG_ VALID_B_1 : 115|1@0+ (1,0) [0|0] "unit" Vector__XXX
	SG_ VALID_A_1 : 118|1@0+ (1,0) [0|0] "unit" Vector__XXX
	SG_ MYSTERY_RELATIVE_VELOCITY_1 : 100|13@0- (1,0) [0|0] "unit" Vector__XXX
	SG_ ABSOLUTE_DISTANCE_1 : 82|13@0+ (0.0176,0.1163) [0|0] "m" Vector__XXX
	SG_ ANGLE_1 : 71|9@0+ (0.0033,0.4509) [0|0] "radians" Vector__XXX
	SG_ BEHIND_FLAG_1 : 56|1@0+ (1,0) [0|0] "unit" Vector_XXX
	SG_ SIGNAL_QUESTION_A_1 : 62|6@0- (1,0) [0|0] "unit" Vector__XXX

	SG_ COUNTER : 23|8@0+ (1,0) [0|0] "unit" Vector__XXX
	SG_ CHECKSUM : 7|16@0+ (1,0) [0|0] "unit" Vector__XXX

BO_ 416 RIGHT_RADAR_8: 64 Vector__XXX
	SG_ NEARBY_WARNING_FLAG_6 : 484|1@0+ (1,0) [0|0] "unit" Vector__XXX
	SG_ INVALID_6 : 473|1@0+ (1,0) [0|0] "unit" Vector__XXX
	SG_ VALID_B_6 : 475|1@0+ (1,0) [0|0] "unit" Vector__XXX
	SG_ VALID_A_6 : 478|1@0+ (1,0) [0|0] "unit" Vector__XXX
	SG_ MYSTERY_RELATIVE_VELOCITY_6 : 460|13@0- (1,0) [0|0] "unit" Vector__XXX
	SG_ ABSOLUTE_DISTANCE_6 : 442|13@0+ (0.0176,0.1163) [0|0] "m" Vector__XXX
	SG_ ANGLE_6 : 431|9@0+ (0.0033,0.4509) [0|0] "radians" Vector__XXX
	SG_ BEHIND_FLAG_6 : 416|1@0+ (1,0) [0|0] "unit" Vector_XXX
	SG_ SIGNAL_QUESTION_A_6 : 422|6@0- (1,0) [0|0] "unit" Vector__XXX

	SG_ NEARBY_WARNING_FLAG_5 : 412|1@0+ (1,0) [0|0] "unit" Vector__XXX
	SG_ INVALID_5 : 401|1@0+ (1,0) [0|0] "unit" Vector__XXX
	SG_ VALID_B_5 : 403|1@0+ (1,0) [0|0] "unit" Vector__XXX
	SG_ VALID_A_5 : 406|1@0+ (1,0) [0|0] "unit" Vector__XXX
	SG_ MYSTERY_RELATIVE_VELOCITY_5 : 388|13@0- (1,0) [0|0] "unit" Vector__XXX
	SG_ ABSOLUTE_DISTANCE_5 : 370|13@0+ (0.0176,0.1163) [0|0] "m" Vector__XXX
	SG_ ANGLE_5 : 359|9@0+ (0.0033,0.4509) [0|0] "radians" Vector__XXX
	SG_ BEHIND_FLAG_5 : 344|1@0+ (1,0) [0|0] "unit" Vector_XXX
	SG_ SIGNAL_QUESTION_A_5 : 350|6@0- (1,0) [0|0] "unit" Vector__XXX

	SG_ NEARBY_WARNING_FLAG_4 : 340|1@0+ (1,0) [0|0] "unit" Vector__XXX
	SG_ INVALID_4 : 329|1@0+ (1,0) [0|0] "unit" Vector__XXX
	SG_ VALID_B_4 : 331|1@0+ (1,0) [0|0] "unit" Vector__XXX
	SG_ VALID_A_4 : 334|1@0+ (1,0) [0|0] "unit" Vector__XXX
	SG_ MYSTERY_RELATIVE_VELOCITY_4 : 316|13@0- (1,0) [0|0] "unit" Vector__XXX
	SG_ ABSOLUTE_DISTANCE_4 : 298|13@0+ (0.0176,0.1163) [0|0] "m" Vector__XXX
	SG_ ANGLE_4 : 287|9@0+ (0.0033,0.4509) [0|0] "radians" Vector__XXX
	SG_ BEHIND_FLAG_4 : 272|1@0+ (1,0) [0|0] "unit" Vector_XXX
	SG_ SIGNAL_QUESTION_A_4 : 278|6@0- (1,0) [0|0] "unit" Vector__XXX

	SG_ NEARBY_WARNING_FLAG_3 : 268|1@0+ (1,0) [0|0] "unit" Vector__XXX
	SG_ INVALID_3 : 257|1@0+ (1,0) [0|0] "unit" Vector__XXX
	SG_ VALID_B_3 : 259|1@0+ (1,0) [0|0] "unit" Vector__XXX
	SG_ VALID_A_3 : 262|1@0+ (1,0) [0|0] "unit" Vector__XXX
	SG_ MYSTERY_RELATIVE_VELOCITY_3 : 244|13@0- (1,0) [0|0] "unit" Vector__XXX
	SG_ ABSOLUTE_DISTANCE_3 : 226|13@0+ (0.0176,0.1163) [0|0] "m" Vector__XXX
	SG_ ANGLE_3 : 215|9@0+ (0.0033,0.4509) [0|0] "radians" Vector__XXX
	SG_ BEHIND_FLAG_3 : 200|1@0+ (1,0) [0|0] "unit" Vector_XXX
	SG_ SIGNAL_QUESTION_A_3 : 206|6@0- (1,0) [0|0] "unit" Vector__XXX

	SG_ NEARBY_WARNING_FLAG_2 : 196|1@0+ (1,0) [0|0] "unit" Vector__XXX
	SG_ INVALID_2 : 185|1@0+ (1,0) [0|0] "unit" Vector__XXX
	SG_ VALID_B_2 : 187|1@0+ (1,0) [0|0] "unit" Vector__XXX
	SG_ VALID_A_2 : 190|1@0+ (1,0) [0|0] "unit" Vector__XXX
	SG_ MYSTERY_RELATIVE_VELOCITY_2 : 172|13@0- (1,0) [0|0] "unit" Vector__XXX
	SG_ ABSOLUTE_DISTANCE_2 : 154|13@0+ (0.0176,0.1163) [0|0] "m" Vector__XXX
	SG_ ANGLE_2 : 143|9@0+ (0.0033,0.4509) [0|0] "radians" Vector__XXX
	SG_ BEHIND_FLAG_2 : 128|1@0+ (1,0) [0|0] "unit" Vector_XXX
	SG_ SIGNAL_QUESTION_A_2 : 134|6@0- (1,0) [0|0] "unit" Vector__XXX

	SG_ NEARBY_WARNING_FLAG_1 : 124|1@0+ (1,0) [0|0] "unit" Vector__XXX
	SG_ INVALID_1 : 113|1@0+ (1,0) [0|0] "unit" Vector__XXX
	SG_ VALID_B_1 : 115|1@0+ (1,0) [0|0] "unit" Vector__XXX
	SG_ VALID_A_1 : 118|1@0+ (1,0) [0|0] "unit" Vector__XXX
	SG_ MYSTERY_RELATIVE_VELOCITY_1 : 100|13@0- (1,0) [0|0] "unit" Vector__XXX
	SG_ ABSOLUTE_DISTANCE_1 : 82|13@0+ (0.0176,0.1163) [0|0] "m" Vector__XXX
	SG_ ANGLE_1 : 71|9@0+ (0.0033,0.4509) [0|0] "radians" Vector__XXX
	SG_ BEHIND_FLAG_1 : 56|1@0+ (1,0) [0|0] "unit" Vector_XXX
	SG_ SIGNAL_QUESTION_A_1 : 62|6@0- (1,0) [0|0] "unit" Vector__XXX

	SG_ COUNTER : 23|8@0+ (1,0) [0|0] "unit" Vector__XXX
	SG_ CHECKSUM : 7|16@0+ (1,0) [0|0] "unit" Vector__XXX

BO_ 419 LEFT_RADAR_9: 64 Vector__XXX
	SG_ NEARBY_WARNING_FLAG_6 : 484|1@0+ (1,0) [0|0] "unit" Vector__XXX
	SG_ INVALID_6 : 473|1@0+ (1,0) [0|0] "unit" Vector__XXX
	SG_ VALID_B_6 : 475|1@0+ (1,0) [0|0] "unit" Vector__XXX
	SG_ VALID_A_6 : 478|1@0+ (1,0) [0|0] "unit" Vector__XXX
	SG_ MYSTERY_RELATIVE_VELOCITY_6 : 460|13@0- (1,0) [0|0] "unit" Vector__XXX
	SG_ ABSOLUTE_DISTANCE_6 : 442|13@0+ (0.0176,0.1163) [0|0] "m" Vector__XXX
	SG_ ANGLE_6 : 431|9@0+ (0.0033,0.4509) [0|0] "radians" Vector__XXX
	SG_ BEHIND_FLAG_6 : 416|1@0+ (1,0) [0|0] "unit" Vector_XXX
	SG_ SIGNAL_QUESTION_A_6 : 422|6@0- (1,0) [0|0] "unit" Vector__XXX

	SG_ NEARBY_WARNING_FLAG_5 : 412|1@0+ (1,0) [0|0] "unit" Vector__XXX
	SG_ INVALID_5 : 401|1@0+ (1,0) [0|0] "unit" Vector__XXX
	SG_ VALID_B_5 : 403|1@0+ (1,0) [0|0] "unit" Vector__XXX
	SG_ VALID_A_5 : 406|1@0+ (1,0) [0|0] "unit" Vector__XXX
	SG_ MYSTERY_RELATIVE_VELOCITY_5 : 388|13@0- (1,0) [0|0] "unit" Vector__XXX
	SG_ ABSOLUTE_DISTANCE_5 : 370|13@0+ (0.0176,0.1163) [0|0] "m" Vector__XXX
	SG_ ANGLE_5 : 359|9@0+ (0.0033,0.4509) [0|0] "radians" Vector__XXX
	SG_ BEHIND_FLAG_5 : 344|1@0+ (1,0) [0|0] "unit" Vector_XXX
	SG_ SIGNAL_QUESTION_A_5 : 350|6@0- (1,0) [0|0] "unit" Vector__XXX

	SG_ NEARBY_WARNING_FLAG_4 : 340|1@0+ (1,0) [0|0] "unit" Vector__XXX
	SG_ INVALID_4 : 329|1@0+ (1,0) [0|0] "unit" Vector__XXX
	SG_ VALID_B_4 : 331|1@0+ (1,0) [0|0] "unit" Vector__XXX
	SG_ VALID_A_4 : 334|1@0+ (1,0) [0|0] "unit" Vector__XXX
	SG_ MYSTERY_RELATIVE_VELOCITY_4 : 316|13@0- (1,0) [0|0] "unit" Vector__XXX
	SG_ ABSOLUTE_DISTANCE_4 : 298|13@0+ (0.0176,0.1163) [0|0] "m" Vector__XXX
	SG_ ANGLE_4 : 287|9@0+ (0.0033,0.4509) [0|0] "radians" Vector__XXX
	SG_ BEHIND_FLAG_4 : 272|1@0+ (1,0) [0|0] "unit" Vector_XXX
	SG_ SIGNAL_QUESTION_A_4 : 278|6@0- (1,0) [0|0] "unit" Vector__XXX

	SG_ NEARBY_WARNING_FLAG_3 : 268|1@0+ (1,0) [0|0] "unit" Vector__XXX
	SG_ INVALID_3 : 257|1@0+ (1,0) [0|0] "unit" Vector__XXX
	SG_ VALID_B_3 : 259|1@0+ (1,0) [0|0] "unit" Vector__XXX
	SG_ VALID_A_3 : 262|1@0+ (1,0) [0|0] "unit" Vector__XXX
	SG_ MYSTERY_RELATIVE_VELOCITY_3 : 244|13@0- (1,0) [0|0] "unit" Vector__XXX
	SG_ ABSOLUTE_DISTANCE_3 : 226|13@0+ (0.0176,0.1163) [0|0] "m" Vector__XXX
	SG_ ANGLE_3 : 215|9@0+ (0.0033,0.4509) [0|0] "radians" Vector__XXX
	SG_ BEHIND_FLAG_3 : 200|1@0+ (1,0) [0|0] "unit" Vector_XXX
	SG_ SIGNAL_QUESTION_A_3 : 206|6@0- (1,0) [0|0] "unit" Vector__XXX

	SG_ NEARBY_WARNING_FLAG_2 : 196|1@0+ (1,0) [0|0] "unit" Vector__XXX
	SG_ INVALID_2 : 185|1@0+ (1,0) [0|0] "unit" Vector__XXX
	SG_ VALID_B_2 : 187|1@0+ (1,0) [0|0] "unit" Vector__XXX
	SG_ VALID_A_2 : 190|1@0+ (1,0) [0|0] "unit" Vector__XXX
	SG_ MYSTERY_RELATIVE_VELOCITY_2 : 172|13@0- (1,0) [0|0] "unit" Vector__XXX
	SG_ ABSOLUTE_DISTANCE_2 : 154|13@0+ (0.0176,0.1163) [0|0] "m" Vector__XXX
	SG_ ANGLE_2 : 143|9@0+ (0.0033,0.4509) [0|0] "radians" Vector__XXX
	SG_ BEHIND_FLAG_2 : 128|1@0+ (1,0) [0|0] "unit" Vector_XXX
	SG_ SIGNAL_QUESTION_A_2 : 134|6@0- (1,0) [0|0] "unit" Vector__XXX

	SG_ NEARBY_WARNING_FLAG_1 : 124|1@0+ (1,0) [0|0] "unit" Vector__XXX
	SG_ INVALID_1 : 113|1@0+ (1,0) [0|0] "unit" Vector__XXX
	SG_ VALID_B_1 : 115|1@0+ (1,0) [0|0] "unit" Vector__XXX
	SG_ VALID_A_1 : 118|1@0+ (1,0) [0|0] "unit" Vector__XXX
	SG_ MYSTERY_RELATIVE_VELOCITY_1 : 100|13@0- (1,0) [0|0] "unit" Vector__XXX
	SG_ ABSOLUTE_DISTANCE_1 : 82|13@0+ (0.0176,0.1163) [0|0] "m" Vector__XXX
	SG_ ANGLE_1 : 71|9@0+ (0.0033,0.4509) [0|0] "radians" Vector__XXX
	SG_ BEHIND_FLAG_1 : 56|1@0+ (1,0) [0|0] "unit" Vector_XXX
	SG_ SIGNAL_QUESTION_A_1 : 62|6@0- (1,0) [0|0] "unit" Vector__XXX

	SG_ COUNTER : 23|8@0+ (1,0) [0|0] "unit" Vector__XXX
	SG_ CHECKSUM : 7|16@0+ (1,0) [0|0] "unit" Vector__XXX

BO_ 420 RIGHT_RADAR_9: 64 Vector__XXX
	SG_ NEARBY_WARNING_FLAG_6 : 484|1@0+ (1,0) [0|0] "unit" Vector__XXX
	SG_ INVALID_6 : 473|1@0+ (1,0) [0|0] "unit" Vector__XXX
	SG_ VALID_B_6 : 475|1@0+ (1,0) [0|0] "unit" Vector__XXX
	SG_ VALID_A_6 : 478|1@0+ (1,0) [0|0] "unit" Vector__XXX
	SG_ MYSTERY_RELATIVE_VELOCITY_6 : 460|13@0- (1,0) [0|0] "unit" Vector__XXX
	SG_ ABSOLUTE_DISTANCE_6 : 442|13@0+ (0.0176,0.1163) [0|0] "m" Vector__XXX
	SG_ ANGLE_6 : 431|9@0+ (0.0033,0.4509) [0|0] "radians" Vector__XXX
	SG_ BEHIND_FLAG_6 : 416|1@0+ (1,0) [0|0] "unit" Vector_XXX
	SG_ SIGNAL_QUESTION_A_6 : 422|6@0- (1,0) [0|0] "unit" Vector__XXX

	SG_ NEARBY_WARNING_FLAG_5 : 412|1@0+ (1,0) [0|0] "unit" Vector__XXX
	SG_ INVALID_5 : 401|1@0+ (1,0) [0|0] "unit" Vector__XXX
	SG_ VALID_B_5 : 403|1@0+ (1,0) [0|0] "unit" Vector__XXX
	SG_ VALID_A_5 : 406|1@0+ (1,0) [0|0] "unit" Vector__XXX
	SG_ MYSTERY_RELATIVE_VELOCITY_5 : 388|13@0- (1,0) [0|0] "unit" Vector__XXX
	SG_ ABSOLUTE_DISTANCE_5 : 370|13@0+ (0.0176,0.1163) [0|0] "m" Vector__XXX
	SG_ ANGLE_5 : 359|9@0+ (0.0033,0.4509) [0|0] "radians" Vector__XXX
	SG_ BEHIND_FLAG_5 : 344|1@0+ (1,0) [0|0] "unit" Vector_XXX
	SG_ SIGNAL_QUESTION_A_5 : 350|6@0- (1,0) [0|0] "unit" Vector__XXX

	SG_ NEARBY_WARNING_FLAG_4 : 340|1@0+ (1,0) [0|0] "unit" Vector__XXX
	SG_ INVALID_4 : 329|1@0+ (1,0) [0|0] "unit" Vector__XXX
	SG_ VALID_B_4 : 331|1@0+ (1,0) [0|0] "unit" Vector__XXX
	SG_ VALID_A_4 : 334|1@0+ (1,0) [0|0] "unit" Vector__XXX
	SG_ MYSTERY_RELATIVE_VELOCITY_4 : 316|13@0- (1,0) [0|0] "unit" Vector__XXX
	SG_ ABSOLUTE_DISTANCE_4 : 298|13@0+ (0.0176,0.1163) [0|0] "m" Vector__XXX
	SG_ ANGLE_4 : 287|9@0+ (0.0033,0.4509) [0|0] "radians" Vector__XXX
	SG_ BEHIND_FLAG_4 : 272|1@0+ (1,0) [0|0] "unit" Vector_XXX
	SG_ SIGNAL_QUESTION_A_4 : 278|6@0- (1,0) [0|0] "unit" Vector__XXX

	SG_ NEARBY_WARNING_FLAG_3 : 268|1@0+ (1,0) [0|0] "unit" Vector__XXX
	SG_ INVALID_3 : 257|1@0+ (1,0) [0|0] "unit" Vector__XXX
	SG_ VALID_B_3 : 259|1@0+ (1,0) [0|0] "unit" Vector__XXX
	SG_ VALID_A_3 : 262|1@0+ (1,0) [0|0] "unit" Vector__XXX
	SG_ MYSTERY_RELATIVE_VELOCITY_3 : 244|13@0- (1,0) [0|0] "unit" Vector__XXX
	SG_ ABSOLUTE_DISTANCE_3 : 226|13@0+ (0.0176,0.1163) [0|0] "m" Vector__XXX
	SG_ ANGLE_3 : 215|9@0+ (0.0033,0.4509) [0|0] "radians" Vector__XXX
	SG_ BEHIND_FLAG_3 : 200|1@0+ (1,0) [0|0] "unit" Vector_XXX
	SG_ SIGNAL_QUESTION_A_3 : 206|6@0- (1,0) [0|0] "unit" Vector__XXX

	SG_ NEARBY_WARNING_FLAG_2 : 196|1@0+ (1,0) [0|0] "unit" Vector__XXX
	SG_ INVALID_2 : 185|1@0+ (1,0) [0|0] "unit" Vector__XXX
	SG_ VALID_B_2 : 187|1@0+ (1,0) [0|0] "unit" Vector__XXX
	SG_ VALID_A_2 : 190|1@0+ (1,0) [0|0] "unit" Vector__XXX
	SG_ MYSTERY_RELATIVE_VELOCITY_2 : 172|13@0- (1,0) [0|0] "unit" Vector__XXX
	SG_ ABSOLUTE_DISTANCE_2 : 154|13@0+ (0.0176,0.1163) [0|0] "m" Vector__XXX
	SG_ ANGLE_2 : 143|9@0+ (0.0033,0.4509) [0|0] "radians" Vector__XXX
	SG_ BEHIND_FLAG_2 : 128|1@0+ (1,0) [0|0] "unit" Vector_XXX
	SG_ SIGNAL_QUESTION_A_2 : 134|6@0- (1,0) [0|0] "unit" Vector__XXX

	SG_ NEARBY_WARNING_FLAG_1 : 124|1@0+ (1,0) [0|0] "unit" Vector__XXX
	SG_ INVALID_1 : 113|1@0+ (1,0) [0|0] "unit" Vector__XXX
	SG_ VALID_B_1 : 115|1@0+ (1,0) [0|0] "unit" Vector__XXX
	SG_ VALID_A_1 : 118|1@0+ (1,0) [0|0] "unit" Vector__XXX
	SG_ MYSTERY_RELATIVE_VELOCITY_1 : 100|13@0- (1,0) [0|0] "unit" Vector__XXX
	SG_ ABSOLUTE_DISTANCE_1 : 82|13@0+ (0.0176,0.1163) [0|0] "m" Vector__XXX
	SG_ ANGLE_1 : 71|9@0+ (0.0033,0.4509) [0|0] "radians" Vector__XXX
	SG_ BEHIND_FLAG_1 : 56|1@0+ (1,0) [0|0] "unit" Vector_XXX
	SG_ SIGNAL_QUESTION_A_1 : 62|6@0- (1,0) [0|0] "unit" Vector__XXX

	SG_ COUNTER : 23|8@0+ (1,0) [0|0] "unit" Vector__XXX
	SG_ CHECKSUM : 7|16@0+ (1,0) [0|0] "unit" Vector__XXX

BO_ 423 LEFT_RADAR_10: 64 Vector__XXX
	SG_ NEARBY_WARNING_FLAG_6 : 484|1@0+ (1,0) [0|0] "unit" Vector__XXX
	SG_ INVALID_6 : 473|1@0+ (1,0) [0|0] "unit" Vector__XXX
	SG_ VALID_B_6 : 475|1@0+ (1,0) [0|0] "unit" Vector__XXX
	SG_ VALID_A_6 : 478|1@0+ (1,0) [0|0] "unit" Vector__XXX
	SG_ MYSTERY_RELATIVE_VELOCITY_6 : 460|13@0- (1,0) [0|0] "unit" Vector__XXX
	SG_ ABSOLUTE_DISTANCE_6 : 442|13@0+ (0.0176,0.1163) [0|0] "m" Vector__XXX
	SG_ ANGLE_6 : 431|9@0+ (0.0033,0.4509) [0|0] "radians" Vector__XXX
	SG_ BEHIND_FLAG_6 : 416|1@0+ (1,0) [0|0] "unit" Vector_XXX
	SG_ SIGNAL_QUESTION_A_6 : 422|6@0- (1,0) [0|0] "unit" Vector__XXX

	SG_ NEARBY_WARNING_FLAG_5 : 412|1@0+ (1,0) [0|0] "unit" Vector__XXX
	SG_ INVALID_5 : 401|1@0+ (1,0) [0|0] "unit" Vector__XXX
	SG_ VALID_B_5 : 403|1@0+ (1,0) [0|0] "unit" Vector__XXX
	SG_ VALID_A_5 : 406|1@0+ (1,0) [0|0] "unit" Vector__XXX
	SG_ MYSTERY_RELATIVE_VELOCITY_5 : 388|13@0- (1,0) [0|0] "unit" Vector__XXX
	SG_ ABSOLUTE_DISTANCE_5 : 370|13@0+ (0.0176,0.1163) [0|0] "m" Vector__XXX
	SG_ ANGLE_5 : 359|9@0+ (0.0033,0.4509) [0|0] "radians" Vector__XXX
	SG_ BEHIND_FLAG_5 : 344|1@0+ (1,0) [0|0] "unit" Vector_XXX
	SG_ SIGNAL_QUESTION_A_5 : 350|6@0- (1,0) [0|0] "unit" Vector__XXX

	SG_ NEARBY_WARNING_FLAG_4 : 340|1@0+ (1,0) [0|0] "unit" Vector__XXX
	SG_ INVALID_4 : 329|1@0+ (1,0) [0|0] "unit" Vector__XXX
	SG_ VALID_B_4 : 331|1@0+ (1,0) [0|0] "unit" Vector__XXX
	SG_ VALID_A_4 : 334|1@0+ (1,0) [0|0] "unit" Vector__XXX
	SG_ MYSTERY_RELATIVE_VELOCITY_4 : 316|13@0- (1,0) [0|0] "unit" Vector__XXX
	SG_ ABSOLUTE_DISTANCE_4 : 298|13@0+ (0.0176,0.1163) [0|0] "m" Vector__XXX
	SG_ ANGLE_4 : 287|9@0+ (0.0033,0.4509) [0|0] "radians" Vector__XXX
	SG_ BEHIND_FLAG_4 : 272|1@0+ (1,0) [0|0] "unit" Vector_XXX
	SG_ SIGNAL_QUESTION_A_4 : 278|6@0- (1,0) [0|0] "unit" Vector__XXX

	SG_ NEARBY_WARNING_FLAG_3 : 268|1@0+ (1,0) [0|0] "unit" Vector__XXX
	SG_ INVALID_3 : 257|1@0+ (1,0) [0|0] "unit" Vector__XXX
	SG_ VALID_B_3 : 259|1@0+ (1,0) [0|0] "unit" Vector__XXX
	SG_ VALID_A_3 : 262|1@0+ (1,0) [0|0] "unit" Vector__XXX
	SG_ MYSTERY_RELATIVE_VELOCITY_3 : 244|13@0- (1,0) [0|0] "unit" Vector__XXX
	SG_ ABSOLUTE_DISTANCE_3 : 226|13@0+ (0.0176,0.1163) [0|0] "m" Vector__XXX
	SG_ ANGLE_3 : 215|9@0+ (0.0033,0.4509) [0|0] "radians" Vector__XXX
	SG_ BEHIND_FLAG_3 : 200|1@0+ (1,0) [0|0] "unit" Vector_XXX
	SG_ SIGNAL_QUESTION_A_3 : 206|6@0- (1,0) [0|0] "unit" Vector__XXX

	SG_ NEARBY_WARNING_FLAG_2 : 196|1@0+ (1,0) [0|0] "unit" Vector__XXX
	SG_ INVALID_2 : 185|1@0+ (1,0) [0|0] "unit" Vector__XXX
	SG_ VALID_B_2 : 187|1@0+ (1,0) [0|0] "unit" Vector__XXX
	SG_ VALID_A_2 : 190|1@0+ (1,0) [0|0] "unit" Vector__XXX
	SG_ MYSTERY_RELATIVE_VELOCITY_2 : 172|13@0- (1,0) [0|0] "unit" Vector__XXX
	SG_ ABSOLUTE_DISTANCE_2 : 154|13@0+ (0.0176,0.1163) [0|0] "m" Vector__XXX
	SG_ ANGLE_2 : 143|9@0+ (0.0033,0.4509) [0|0] "radians" Vector__XXX
	SG_ BEHIND_FLAG_2 : 128|1@0+ (1,0) [0|0] "unit" Vector_XXX
	SG_ SIGNAL_QUESTION_A_2 : 134|6@0- (1,0) [0|0] "unit" Vector__XXX

	SG_ NEARBY_WARNING_FLAG_1 : 124|1@0+ (1,0) [0|0] "unit" Vector__XXX
	SG_ INVALID_1 : 113|1@0+ (1,0) [0|0] "unit" Vector__XXX
	SG_ VALID_B_1 : 115|1@0+ (1,0) [0|0] "unit" Vector__XXX
	SG_ VALID_A_1 : 118|1@0+ (1,0) [0|0] "unit" Vector__XXX
	SG_ MYSTERY_RELATIVE_VELOCITY_1 : 100|13@0- (1,0) [0|0] "unit" Vector__XXX
	SG_ ABSOLUTE_DISTANCE_1 : 82|13@0+ (0.0176,0.1163) [0|0] "m" Vector__XXX
	SG_ ANGLE_1 : 71|9@0+ (0.0033,0.4509) [0|0] "radians" Vector__XXX
	SG_ BEHIND_FLAG_1 : 56|1@0+ (1,0) [0|0] "unit" Vector_XXX
	SG_ SIGNAL_QUESTION_A_1 : 62|6@0- (1,0) [0|0] "unit" Vector__XXX

	SG_ COUNTER : 23|8@0+ (1,0) [0|0] "unit" Vector__XXX
	SG_ CHECKSUM : 7|16@0+ (1,0) [0|0] "unit" Vector__XXX

BO_ 425 RIGHT_RADAR_10: 64 Vector__XXX
	SG_ NEARBY_WARNING_FLAG_6 : 484|1@0+ (1,0) [0|0] "unit" Vector__XXX
	SG_ INVALID_6 : 473|1@0+ (1,0) [0|0] "unit" Vector__XXX
	SG_ VALID_B_6 : 475|1@0+ (1,0) [0|0] "unit" Vector__XXX
	SG_ VALID_A_6 : 478|1@0+ (1,0) [0|0] "unit" Vector__XXX
	SG_ MYSTERY_RELATIVE_VELOCITY_6 : 460|13@0- (1,0) [0|0] "unit" Vector__XXX
	SG_ ABSOLUTE_DISTANCE_6 : 442|13@0+ (0.0176,0.1163) [0|0] "m" Vector__XXX
	SG_ ANGLE_6 : 431|9@0+ (0.0033,0.4509) [0|0] "radians" Vector__XXX
	SG_ BEHIND_FLAG_6 : 416|1@0+ (1,0) [0|0] "unit" Vector_XXX
	SG_ SIGNAL_QUESTION_A_6 : 422|6@0- (1,0) [0|0] "unit" Vector__XXX

	SG_ NEARBY_WARNING_FLAG_5 : 412|1@0+ (1,0) [0|0] "unit" Vector__XXX
	SG_ INVALID_5 : 401|1@0+ (1,0) [0|0] "unit" Vector__XXX
	SG_ VALID_B_5 : 403|1@0+ (1,0) [0|0] "unit" Vector__XXX
	SG_ VALID_A_5 : 406|1@0+ (1,0) [0|0] "unit" Vector__XXX
	SG_ MYSTERY_RELATIVE_VELOCITY_5 : 388|13@0- (1,0) [0|0] "unit" Vector__XXX
	SG_ ABSOLUTE_DISTANCE_5 : 370|13@0+ (0.0176,0.1163) [0|0] "m" Vector__XXX
	SG_ ANGLE_5 : 359|9@0+ (0.0033,0.4509) [0|0] "radians" Vector__XXX
	SG_ BEHIND_FLAG_5 : 344|1@0+ (1,0) [0|0] "unit" Vector_XXX
	SG_ SIGNAL_QUESTION_A_5 : 350|6@0- (1,0) [0|0] "unit" Vector__XXX

	SG_ NEARBY_WARNING_FLAG_4 : 340|1@0+ (1,0) [0|0] "unit" Vector__XXX
	SG_ INVALID_4 : 329|1@0+ (1,0) [0|0] "unit" Vector__XXX
	SG_ VALID_B_4 : 331|1@0+ (1,0) [0|0] "unit" Vector__XXX
	SG_ VALID_A_4 : 334|1@0+ (1,0) [0|0] "unit" Vector__XXX
	SG_ MYSTERY_RELATIVE_VELOCITY_4 : 316|13@0- (1,0) [0|0] "unit" Vector__XXX
	SG_ ABSOLUTE_DISTANCE_4 : 298|13@0+ (0.0176,0.1163) [0|0] "m" Vector__XXX
	SG_ ANGLE_4 : 287|9@0+ (0.0033,0.4509) [0|0] "radians" Vector__XXX
	SG_ BEHIND_FLAG_4 : 272|1@0+ (1,0) [0|0] "unit" Vector_XXX
	SG_ SIGNAL_QUESTION_A_4 : 278|6@0- (1,0) [0|0] "unit" Vector__XXX

	SG_ NEARBY_WARNING_FLAG_3 : 268|1@0+ (1,0) [0|0] "unit" Vector__XXX
	SG_ INVALID_3 : 257|1@0+ (1,0) [0|0] "unit" Vector__XXX
	SG_ VALID_B_3 : 259|1@0+ (1,0) [0|0] "unit" Vector__XXX
	SG_ VALID_A_3 : 262|1@0+ (1,0) [0|0] "unit" Vector__XXX
	SG_ MYSTERY_RELATIVE_VELOCITY_3 : 244|13@0- (1,0) [0|0] "unit" Vector__XXX
	SG_ ABSOLUTE_DISTANCE_3 : 226|13@0+ (0.0176,0.1163) [0|0] "m" Vector__XXX
	SG_ ANGLE_3 : 215|9@0+ (0.0033,0.4509) [0|0] "radians" Vector__XXX
	SG_ BEHIND_FLAG_3 : 200|1@0+ (1,0) [0|0] "unit" Vector_XXX
	SG_ SIGNAL_QUESTION_A_3 : 206|6@0- (1,0) [0|0] "unit" Vector__XXX

	SG_ NEARBY_WARNING_FLAG_2 : 196|1@0+ (1,0) [0|0] "unit" Vector__XXX
	SG_ INVALID_2 : 185|1@0+ (1,0) [0|0] "unit" Vector__XXX
	SG_ VALID_B_2 : 187|1@0+ (1,0) [0|0] "unit" Vector__XXX
	SG_ VALID_A_2 : 190|1@0+ (1,0) [0|0] "unit" Vector__XXX
	SG_ MYSTERY_RELATIVE_VELOCITY_2 : 172|13@0- (1,0) [0|0] "unit" Vector__XXX
	SG_ ABSOLUTE_DISTANCE_2 : 154|13@0+ (0.0176,0.1163) [0|0] "m" Vector__XXX
	SG_ ANGLE_2 : 143|9@0+ (0.0033,0.4509) [0|0] "radians" Vector__XXX
	SG_ BEHIND_FLAG_2 : 128|1@0+ (1,0) [0|0] "unit" Vector_XXX
	SG_ SIGNAL_QUESTION_A_2 : 134|6@0- (1,0) [0|0] "unit" Vector__XXX

	SG_ NEARBY_WARNING_FLAG_1 : 124|1@0+ (1,0) [0|0] "unit" Vector__XXX
	SG_ INVALID_1 : 113|1@0+ (1,0) [0|0] "unit" Vector__XXX
	SG_ VALID_B_1 : 115|1@0+ (1,0) [0|0] "unit" Vector__XXX
	SG_ VALID_A_1 : 118|1@0+ (1,0) [0|0] "unit" Vector__XXX
	SG_ MYSTERY_RELATIVE_VELOCITY_1 : 100|13@0- (1,0) [0|0] "unit" Vector__XXX
	SG_ ABSOLUTE_DISTANCE_1 : 82|13@0+ (0.0176,0.1163) [0|0] "m" Vector__XXX
	SG_ ANGLE_1 : 71|9@0+ (0.0033,0.4509) [0|0] "radians" Vector__XXX
	SG_ BEHIND_FLAG_1 : 56|1@0+ (1,0) [0|0] "unit" Vector_XXX
	SG_ SIGNAL_QUESTION_A_1 : 62|6@0- (1,0) [0|0] "unit" Vector__XXX

	SG_ COUNTER : 23|8@0+ (1,0) [0|0] "unit" Vector__XXX
	SG_ CHECKSUM : 7|16@0+ (1,0) [0|0] "unit" Vector__XXX

//BO_ 407 COMPLEX_SENSOR_3: 64 XXX
 //SG_ REPEATED_NON_DECREASING : 39|18@0+ (1,0) [0|200000] "" XXX

BO_ 427 ACCEL_STEER: 64 XXX
 SG_ MYSTERY_STATE : 52|4@0+ (1,0) [0|16] "" XXX
 SG_ STEERING_RATE : 63|7@0+ (1,-75) [0|40000] "" XXX
 SG_ STEER_ANGLE : 71|12@0+ (1,-1500) [0|4000] "" XXX
 SG_ ACCEL_X : 231|12@0+ (0.1,-2000) [0|4000] "" XXX
 SG_ ACCEL_X_REPEAT : 235|12@0+ (0.1,-2000) [0|4000] "" XXX
 SG_ YAW : 255|12@0+ (0.1,-2000) [0|4000] "" XXX
 SG_ YAW_REPEAT : 259|12@0+ (0.1,-2000) [0|4000] "" XXX
 SG_ STEER_ANGLE_REPEAT : 315|12@0+ (1,-3050) [0|4000] "" XXX
 SG_ STEER_ANGLE_BUT_NOT : 343|15@0+ (1,0) [0|40000] "" XXX
 SG_ MYSTERY_STATE2 : 344|1@0+ (1,0) [0|1] "" XXX
 SG_ STEER_ANGLE_REPEAT_AGAIN : 359|11@0+ (1,-1000) [0|2000] "" XXX

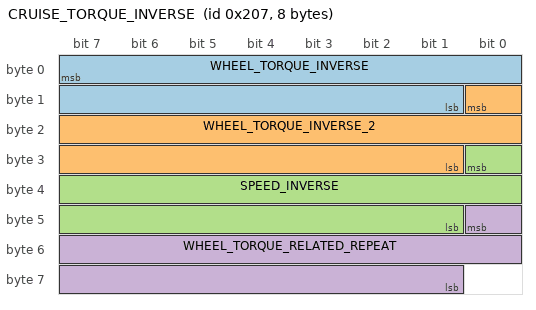
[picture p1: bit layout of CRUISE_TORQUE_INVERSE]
BO_ 519 CRUISE_TORQUE_INVERSE: 8 XXX
 SG_ WHEEL_TORQUE_INVERSE : 7|15@0+ (1,0) [0|2000] "" XXX
 SG_ WHEEL_TORQUE_INVERSE_2 : 8|16@0+ (1,0) [0|20000] "" XXX
 SG_ SPEED_INVERSE : 24|16@0+ (1,0) [0|60000] "" XXX
 SG_ WHEEL_TORQUE_RELATED_REPEAT : 40|16@0+ (1,0) [0|60000] "" XXX

BO_ 534 BUTTONS_1: 4 XXX
 SG_ SOMETHING_MOSTLY_ON: 23|1@0+ (1,0) [0|1] "" XXX
 SG_ DISCRETE_LOW_SPEEDS : 28|4@0+ (1,0) [0|8] "" XXX

BO_ 544 BRAKE_ENGINE: 3 XXX
 SG_ STOPPED_STATE : 22|1@0+ (1,0) [0|1] "" XXX

BO_ 548 BRAKE: 7 XXX
 SG_ BRAKE_STATE : 7|5@0+ (1,0) [0|1024] "" XXX
 SG_ BRAKE_PEDAL : 2|10@0+ (1,0) [0|1024] "" XXX

BO_ 550 WHEEL_ENCODERS: 64 XXX
 SG_ WHEEL_SPEED_FL : 111|16@0+ (0.0057,0) [0|65535] "" XXX
 SG_ WHEEL_SPEED_FR : 127|16@0+ (0.0057,0) [0|65535] "" XXX
 SG_ WHEEL_SPEED_FRONT : 143|16@0+ (0.01,0) [0|65535] "" XXX
 SG_ WHEEL_SPEED_RR : 287|16@0+ (0.0057,0) [0|65535] "" XXX
 SG_ WHEEL_SPEED_RL : 303|16@0+ (0.0057,0) [0|65535] "" XXX
 SG_ WHEEL_SPEED_REAR : 319|16@0+ (0.01,0) [0|65535] "" XXX

BO_ 771 SONAR : 64 XXX
 SG_ SONAR1 : 135|6@0+ (0.0833,0) [0|300] "" XXX
 SG_ SONAR2 : 143|6@0+ (0.0833,0) [0|300] "" XXX
 SG_ SONAR3 : 151|6@0+ (0.0833,0) [0|300] "" XXX
 SG_ SONAR4 : 159|6@0+ (0.0833,0) [0|300] "" XXX
 SG_ SONAR5 : 167|6@0+ (0.0833,0) [0|300] "" XXX
 SG_ SONAR6 : 175|6@0+ (0.0833,0) [0|300] "" XXX

 SG_ SONAR7 : 223|6@0+ (0.0833,0) [0|300] "" XXX
 SG_ SONAR8 : 231|6@0+ (0.0833,0) [0|300] "" XXX
 SG_ SONAR9 : 239|6@0+ (0.0833,0) [0|300] "" XXX
 SG_ SONAR10 : 247|6@0+ (0.0833,0) [0|300] "" XXX
 SG_ SONAR11 : 255|6@0+ (0.0833,0) [0|300] "" XXX
 SG_ SONAR12 : 263|6@0+ (0.0833,0) [0|300] "" XXX

 SG_ SONAR13 : 311|6@0+ (0.0833,0) [0|300] "" XXX
 SG_ SONAR14 : 319|6@0+ (0.0833,0) [0|300] "" XXX
 SG_ SONAR15 : 327|6@0+ (0.0833,0) [0|300] "" XXX
 SG_ SONAR16 : 335|6@0+ (0.0833,0) [0|300] "" XXX
 SG_ SONAR17 : 343|6@0+ (0.0833,0) [0|300] "" XXX
 SG_ SONAR18 : 351|6@0+ (0.0833,0) [0|300] "" XXX
 SG_ SONAR19 : 359|6@0+ (0.0833,0) [0|300] "" XXX
 SG_ SONAR20 : 367|6@0+ (0.0833,0) [0|300] "" XXX

 //SG_ GEAR : 219|3@0+ (1,0) [0|8] "" XXX
 //SG_ DRIVE : 419|1@0+ (1,0) [0|1] "" XXX

BO_ 768 STEER_TORQUE_SENSOR2: 2 XXX
 SG_ STEERING_TORQUE : 6|7@0+ (1,0) [0|127] "" XXX
 SG_ STEERING_PRESSED : 15|1@0+ (-1,1) [0|7] "" XXX

//BO_ 783 CRUISE_STATE: 3 XXX
// SG_ CRUISE_ENABLED : 3|1@0+ (1,0) [0|1] "" XXX

BO_ 779 BONUS_RADAR1: 64 XXX
 SG_ SIG1 : 38|12@0+ (1,0) [0|1000] "" XXX
 SG_ SIG2 : 53|8@0+ (1,0) [0|1000] "" XXX
 SG_ SIG3 : 70|8@0+ (1,0) [0|1000] "" XXX
 SG_ SIG4 : 78|9@0+ (1,0) [0|1000] "" XXX

BO_ 783 BONUS_RADAR2: 64 XXX
 SG_ SIG1 : 38|12@0+ (1,0) [0|1000] "" XXX
 SG_ SIG2 : 53|8@0+ (1,0) [0|1000] "" XXX
 SG_ SIG3 : 70|8@0+ (1,0) [0|1000] "" XXX
 SG_ SIG4 : 78|9@0+ (1,0) [0|1000] "" XXX

BO_ 875 EightSevenFive: 32 XXX
 SG_ NOISY : 157|6@0+ (1,0) [0|100] "" XXX
 SG_ ANGLES : 224|10@0+ (1,0) [0|100] "" XXX

BO_ 888 EightEightEight: 32 XXX
 SG_ SEISMIC_NOISY_120 : 157|6@0+ (1,0) [0|100] "" XXX
 SG_ ANGLES : 224|10@0+ (1,0) [0|100] "" XXX

BO_ 923 SIDE_RADAR1: 64 XXX
 SG_ SIG1_LEAD : 267|9@0+ (0.2,0) [0|1000] "" XXX
 SG_ SIG2_VEL : 274|16@0+ (0.01,0) [0|1000] "" XXX
 SG_ SIG3_ANGLEH : 301|12@0+ (0.01,0) [0|1000] "" XXX
 SG_ SIG4_ANGLEV : 305|9@0+ (0.2,0) [0|1000] "" XXX

BO_ 924 SIDE_RADAR2: 64 XXX
 SG_ SIG1_LEAD : 385|9@0+ (0.2,0) [0|1000] "" XXX
 SG_ SIG2_VEL : 392|16@0+ (0.01,0) [0|1000] "" XXX
 SG_ SIG3_ANGLEH : 419|12@0+ (0.01,0) [0|1000] "" XXX
 SG_ SIG4_ANGLEV : 439|9@0+ (0.2,0) [0|1000] "" XXX

BO_ 936 SIDE_RADAR3: 64 XXX
 SG_ SIG1_LEAD : 31|9@0+ (0.2,0) [0|1000] "" XXX
 SG_ SIG2_VEL : 38|16@0+ (0.01,0) [0|1000] "" XXX
 SG_ SIG3_ANGLEH : 49|12@0+ (0.01,0) [0|1000] "" XXX
 SG_ SIG4_ANGLEV : 69|9@0+ (0.2,0) [0|1000] "" XXX

BO_ 951 SIDE_RADAR4: 64 XXX
 SG_ SIG1_LEAD : 267|9@0+ (0.2,0) [0|1000] "" XXX
 SG_ SIG2_VEL : 274|16@0+ (0.01,0) [0|1000] "" XXX
 SG_ SIG3_ANGLEH : 301|12@0+ (0.01,0) [0|1000] "" XXX
 SG_ SIG4_ANGLEV : 305|9@0+ (0.2,0) [0|1000] "" XXX

BO_ 954 SIDE_RADAR5: 64 XXX
 SG_ SIG1_LEAD : 385|9@0+ (0.2,0) [0|1000] "" XXX
 SG_ SIG2_VEL : 392|16@0+ (0.01,0) [0|1000] "" XXX
 SG_ SIG3_ANGLEH : 419|12@0+ (0.01,0) [0|1000] "" XXX
 SG_ SIG4_ANGLEV : 439|9@0+ (0.2,0) [0|1000] "" XXX

BO_ 958 SIDE_RADAR6: 64 XXX
 SG_ SIG1_LEAD : 31|9@0+ (0.2,0) [0|1000] "" XXX
 SG_ SIG2_VEL : 38|16@0+ (0.01,0) [0|1000] "" XXX
 SG_ SIG3_ANGLEH : 49|12@0+ (0.01,0) [0|1000] "" XXX
 SG_ SIG4_ANGLEV : 69|9@0+ (0.2,0) [0|1000] "" XXX

BO_ 1018 SPEED2: 32 XXX
 SG_ SPEED : 37|10@0+ (1,0) [0|1000] "" XXX
 SG_ SPEED2 : 52|9@0+ (1,0) [0|1000] "" XXX
 SG_ INTERESTING_DECREASING_SIGNAL : 172|12@0+ (1,0) [0|1000] "" XXX
 SG_ BRAKE_ON : 234|1@0+ (1,0) [0|1] "" XXX
 SG_ ANOTHER_STATE : 233|1@0+ (1,0) [0|1] "" XXX
 SG_ COUNTER : 247|2@0+ (1,0) [0|3] "" XXX

BO_ 1055 GEARBOX: 2 XXX
 SG_ SPORTS_MODE : 13|1@0+ (1,0) [0|1] "" XXX
 SG_ GEAR_SHIFTER : 5|3@0+ (1,0) [0|255] "" XXX

BO_ 1081 ODOMETER: 6 XXX
 SG_ UNKNOWN1 : 7|8@0+ (1,-75) [0|200] "" XXX
 SG_ ODOMETER : 23|20@0+ (1,0) [0|1000000] "m" XXX

BO_ 1105 UNKNOWN_STATE : 24 XXX
 SG_ MYSTERY_NOISY_DISCRETE_STATE : 68|7@0+ (1,0) [0|100] "" XXX
 SG_ SPEEDOMETER : 72|8@0+ (1,0) [0|100] "" XXX

BO_ 1107 ELEVENOHSEVEN: 12 XXX
 SG_ SIGNAL1 : 43|1@0+ (1,0) [0|1] "" XXX
 SG_ SIGNAL2 : 48|9@0+ (1,0) [0|200] "" XXX
 SG_ SIGNAL2_REPEAT : 72|9@0+ (1,0) [0|200] "" XXX

BO_ 1119 WHEEL_BUTTONS: 20 XXX
 SG_ SIGNAL1 : 48|3@0+ (1,0) [0|1] "" XXX
 SG_ LKAS_LDW_ON : 55|1@0+ (1,0) [0|1] "" XXX
 SG_ ACC_BTNS : 61|3@0+ (1,0) [0|1] "" XXX

BO_ 1137 UNKNOWN_247: 8 XXX
 SG_ UNKNOWN2: 40|6@0+ (1,0) [0|1] "" XXX
 SG_ UNKNOWN1: 48|6@0+ (1,0) [0|1] "" XXX

BO_ 1356 LKAS_SETTINGS_2: 8 XXX
 SG_ TWO_BIT_STATE : 45|2@0+ (1,0) [0|3] "" XXX

BO_ 1487 ACC_HUD: 48 XXX
 SG_ SYSTEM_ON : 94|1@0+ (1,0) [0|1] "" XXX
 SG_ MINICAR : 142|1@0+ (1,0) [0|1] "" XXX
 //SG_ HUD_STATE1 : 153|2@0+ (1,0) [0|4] "" XXX
 SG_ SET_SPEED : 158|7@0+ (1,0) [0|90] "" XXX
 //lsb is sysetm on/off
 SG_ SET_DISTANCE : 166|2@0+ (1,0) [0|3] "" XXX
 SG_ HUD_STATES : 177|5@0+ (1,0) [0|32] "" XXX
 SG_ STATE_SIGNAL : 287|4@0+ (1,0) [0|16] "" XXX

BO_ 1459 GEAR: 4 XXX
 SG_ REVERSE : 8|1@0+ (1,0) [0|1] "" XXX

BO_ 1687 SOMETHING_INTERESTING: 16 XXX
 SG_ MY_SIGNAL : 46|6@0+ (1,0) [0|1000] "" XXX

BO_ 1693 SOMETHING_SIGNED: 16 XXX
 SG_ OVERFLOW : 46|6@0+ (1,0) [0|1000] "" XXX

VAL_ 1119 ACC_BTNS 0 "none" 1 "resume" 2 "set" 3 "distance" 4 "cancel" 5 "system_toggle";
VAL_ 308 CRUISE_STATE 1 "off" 9 "hold_waiting_user_cmd" 13 "disabled" 25 "enabled" 29 "unknown"
////VAL_ 921 CRUISE_CONTROL_STATE 2 "disabled" 11 "hold" 10 "hold_waiting_user_cmd" 6 "enabled" 5 "faulted" 0 "off";
